[part 1 of 4: packages /MICROSAR/Dcm_swc to /MICROSAR/Dcm_swc/ComponentTypes]
AUTOSAR XML (schema 4-2-2)
package /MICROSAR/Dcm_swc
  mode declaration group DcmEcuReset: category=EXPLICIT_ORDER, initial-mode=NONE, on-transition-value=7
    7 x mode:
      NONE: value=0
      HARD: value=1
      KEYONOFF: value=2
      SOFT: value=3
      JUMPTOBOOTLOADER: value=4
      JUMPTOSYSSUPPLIERBOOTLOADER: value=5
      EXECUTE: value=6
  mode declaration group DcmDiagnosticSessionControl: category=EXPLICIT_ORDER, initial-mode=DEFAULT_SESSION, on-transition-value=255
    mode DEFAULT_SESSION: value=1
    mode PROGRAMMING_SESSION: value=2
    mode EXTENDED_SESSION: value=3
  data type mapping set DcmMappingSet  # Contains mapping for ModeDeclarationGroups which are provided by Dcm.
    mode-request-type-maps:
      implementation-data-type=Dcm_EcuResetType, mode-group=DcmEcuReset
      implementation-data-type=Dcm_DiagnosticSessionControlType, mode-group=DcmDiagnosticSessionControl
package /MICROSAR/Dcm_swc/ComponentTypes
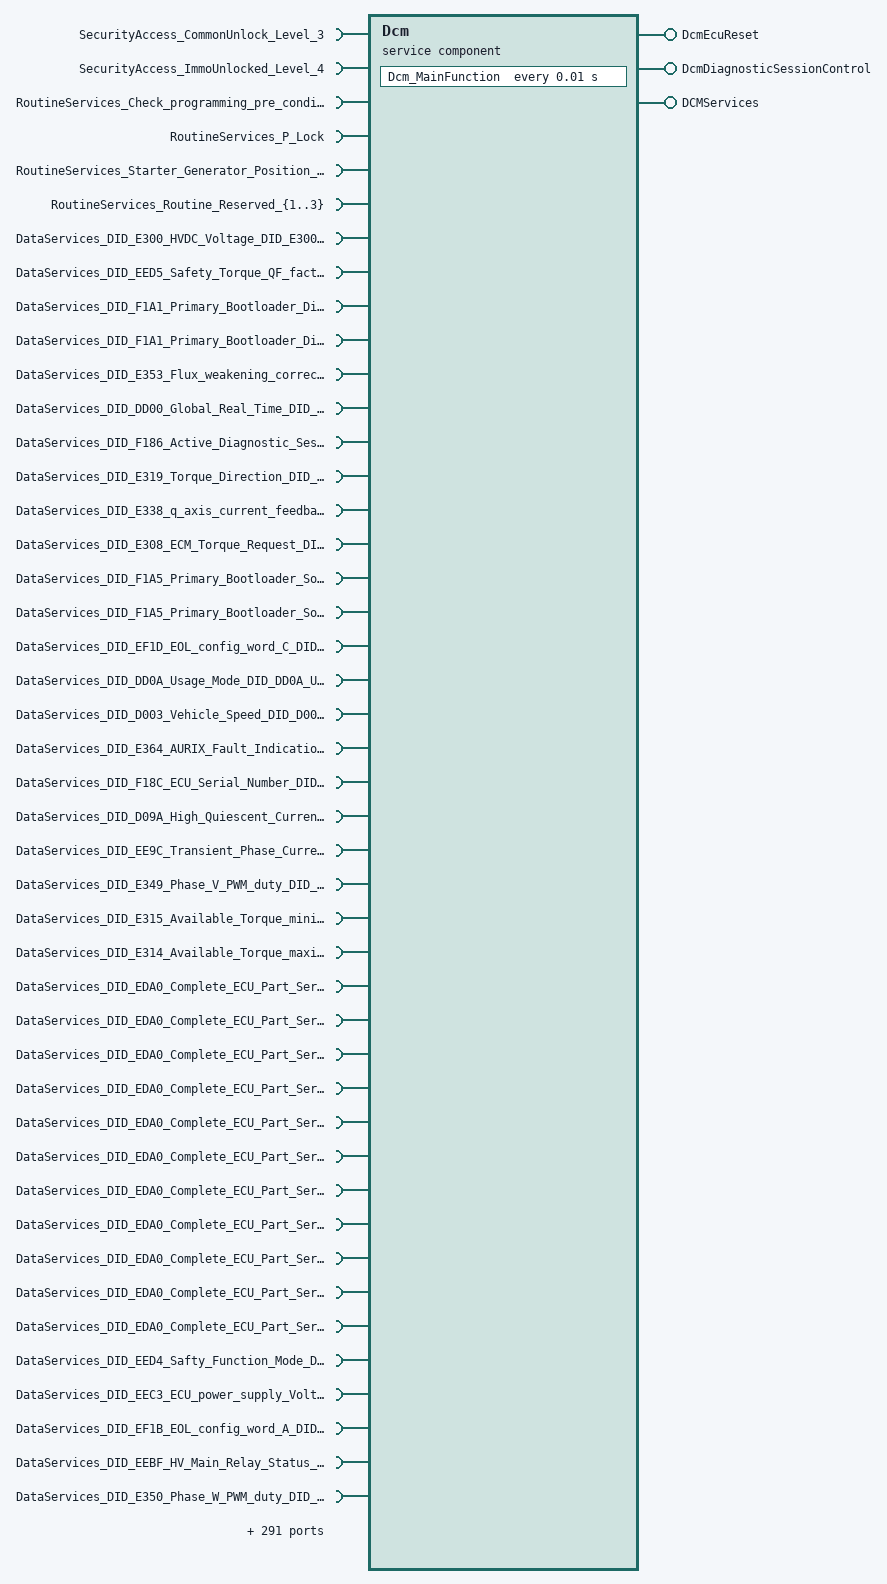
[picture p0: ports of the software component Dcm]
  service sw component type Dcm: category=SERVICE_COMPONENT
    provide port DcmEcuReset: mode-switch-sender-com-spec{mode-group=DcmEcuReset, mode-switched-ack=timeout=0}, provided-interface=DcmEcuReset
    provide port DcmDiagnosticSessionControl: provided-interface=DcmDiagnosticSessionControl
    provide port DCMServices: provided-interface=DCMServices
    346 x require port:
      SecurityAccess_CommonUnlock_Level_3: required-interface=SecurityAccess_CommonUnlock_Level_3
      SecurityAccess_ImmoUnlocked_Level_4: required-interface=SecurityAccess_ImmoUnlocked_Level_4
      RoutineServices_Check_programming_pre_conditions: required-interface=RoutineServices_Check_programming_pre_conditions
      RoutineServices_P_Lock: required-interface=RoutineServices_P_Lock
      RoutineServices_Starter_Generator_Position_Sensors_Calibration: required-interface=RoutineServices_Starter_Generator_Position_Sensors_Calibration
      RoutineServices_Routine_Reserved_{1..3}: required-interface=RoutineServices_Routine_Reserved_{1..3}
      DataServices_DID_E300_HVDC_Voltage_DID_E300_HVDC_Voltage: required-interface=DataServices_DID_E300_HVDC_Voltage_DID_E300_HVDC_Voltage
      DataServices_DID_EED5_Safety_Torque_QF_factor_EED5_Safety_Torque_Quality_factor: required-interface=DataServices_DID_EED5_Safety_Torque_QF_factor_EED5_Safety_Torque_Quality_factor
      DataServices_DID_F1A1_Primary_Bootloader_Diagnostic_Database_Part_Number_Geely_ASCII_part: required-interface=DataServices_DID_F1A1_Primary_Bootloader_Diagnostic_Database_Part_Number_Geely_ASCII_part
      DataServices_DID_F1A1_Primary_Bootloader_Diagnostic_Database_Part_Number_Geely_BCD_part: required-interface=DataServices_DID_F1A1_Primary_Bootloader_Diagnostic_Database_Part_Number_Geely_BCD_part
      DataServices_DID_E353_Flux_weakening_correction_factor_DID_E353_Flux_weakening_correction_factor: required-interface=DataServices_DID_E353_Flux_weakening_correction_factor_DID_E353_Flux_weakening_correction_factor
      DataServices_DID_DD00_Global_Real_Time_DID_DD00_Global_Real_Time: required-interface=DataServices_DID_DD00_Global_Real_Time_DID_DD00_Global_Real_Time
      DataServices_DID_F186_Active_Diagnostic_Session_DID_F186_Active_Diagnostic_Session: required-interface=DataServices_DID_F186_Active_Diagnostic_Session_DID_F186_Active_Diagnostic_Session
      DataServices_DID_E319_Torque_Direction_DID_E319_Torque_Direction: required-interface=DataServices_DID_E319_Torque_Direction_DID_E319_Torque_Direction
      DataServices_DID_E338_q_axis_current_feedback_DID_E338_q_axis_current_feedback: required-interface=DataServices_DID_E338_q_axis_current_feedback_DID_E338_q_axis_current_feedback
      DataServices_DID_E308_ECM_Torque_Request_DID_E308_ECM_Torque_Request: required-interface=DataServices_DID_E308_ECM_Torque_Request_DID_E308_ECM_Torque_Request
      DataServices_DID_F1A5_Primary_Bootloader_Software_Part_Number_Geely_ASCII_part: required-interface=DataServices_DID_F1A5_Primary_Bootloader_Software_Part_Number_Geely_ASCII_part
      DataServices_DID_F1A5_Primary_Bootloader_Software_Part_Number_Geely_BCD_part: required-interface=DataServices_DID_F1A5_Primary_Bootloader_Software_Part_Number_Geely_BCD_part
      DataServices_DID_EF1D_EOL_config_word_C_DID_EF1D_EOL_config_word_C: required-interface=DataServices_DID_EF1D_EOL_config_word_C_DID_EF1D_EOL_config_word_C
      DataServices_DID_DD0A_Usage_Mode_DID_DD0A_Usage_Mode: required-interface=DataServices_DID_DD0A_Usage_Mode_DID_DD0A_Usage_Mode
      DataServices_DID_D003_Vehicle_Speed_DID_D003_Vehicle_Speed: required-interface=DataServices_DID_D003_Vehicle_Speed_DID_D003_Vehicle_Speed
      DataServices_DID_E364_AURIX_Fault_Indication_DID_E364_AURIX_Fault_Indication: required-interface=DataServices_DID_E364_AURIX_Fault_Indication_DID_E364_AURIX_Fault_Indication
      DataServices_DID_F18C_ECU_Serial_Number_DID_F18C_ECU_Serial_Number: required-interface=DataServices_DID_F18C_ECU_Serial_Number_DID_F18C_ECU_Serial_Number
      DataServices_DID_D09A_High_Quiescent_Current_Function_Activation_Deactivation_DID_D09A_High_Quiescent_Current_Function_CD3E51C5: required-interface=DataServices_DID_D09A_High_Quiescent_Current_Function_Activation_Deactivation_DID_D09A_High_Quiescent_Current_Function_CD3E51C5
      DataServices_DID_EE9C_Transient_Phase_Current_A_DID_EE9C_Transient_Phase_Current_A: required-interface=DataServices_DID_EE9C_Transient_Phase_Current_A_DID_EE9C_Transient_Phase_Current_A
      DataServices_DID_E349_Phase_V_PWM_duty_DID_E349_Phase_V_PWM_duty: required-interface=DataServices_DID_E349_Phase_V_PWM_duty_DID_E349_Phase_V_PWM_duty
      DataServices_DID_E315_Available_Torque_minimum_DID_E315_Available_Torque_minimum: required-interface=DataServices_DID_E315_Available_Torque_minimum_DID_E315_Available_Torque_minimum
      DataServices_DID_E314_Available_Torque_maximum_DID_E314_Available_Torque_maximum: required-interface=DataServices_DID_E314_Available_Torque_maximum_DID_E314_Available_Torque_maximum
      DataServices_DID_EDA0_Complete_ECU_Part_Serial_Number_s_DID_F12E_1_Total_number_of_ECU_Software_Part_Numbers: required-interface=DataServices_DID_EDA0_Complete_ECU_Part_Serial_Number_s_DID_F12E_1_Total_number_of_ECU_Software_Part_Numbers
      DataServices_DID_EDA0_Complete_ECU_Part_Serial_Number_s_DID_F12A_ECU_Delivery_Assembly_Part_Number1_1: required-interface=DataServices_DID_EDA0_Complete_ECU_Part_Serial_Number_s_DID_F12A_ECU_Delivery_Assembly_Part_Number1_1
      DataServices_DID_EDA0_Complete_ECU_Part_Serial_Number_s_Reserved: required-interface=DataServices_DID_EDA0_Complete_ECU_Part_Serial_Number_s_Reserved
      DataServices_DID_EDA0_Complete_ECU_Part_Serial_Number_s_DID_F12B_ECU_Delivery_Assembly_Part_Number: required-interface=DataServices_DID_EDA0_Complete_ECU_Part_Serial_Number_s_DID_F12B_ECU_Delivery_Assembly_Part_Number
      DataServices_DID_EDA0_Complete_ECU_Part_Serial_Number_s_DID_F18C_ECU_Serial_Number: required-interface=DataServices_DID_EDA0_Complete_ECU_Part_Serial_Number_s_DID_F18C_ECU_Serial_Number
      DataServices_DID_EDA0_Complete_ECU_Part_Serial_Number_s_ASCII_part: required-interface=DataServices_DID_EDA0_Complete_ECU_Part_Serial_Number_s_ASCII_part
      DataServices_DID_EDA0_Complete_ECU_Part_Serial_Number_s_DID_F12B_ECU_Delivery_Assembly_Part_Number1: required-interface=DataServices_DID_EDA0_Complete_ECU_Part_Serial_Number_s_DID_F12B_ECU_Delivery_Assembly_Part_Number1
      DataServices_DID_EDA0_Complete_ECU_Part_Serial_Number_s_F120_Application_Diagnostic_Database_Part_Number1: required-interface=DataServices_DID_EDA0_Complete_ECU_Part_Serial_Number_s_F120_Application_Diagnostic_Database_Part_Number1
      DataServices_DID_EDA0_Complete_ECU_Part_Serial_Number_s_F120_Application_Diagnostic_Database_Part_Number: required-interface=DataServices_DID_EDA0_Complete_ECU_Part_Serial_Number_s_F120_Application_Diagnostic_Database_Part_Number
      DataServices_DID_EDA0_Complete_ECU_Part_Serial_Number_s_BCD_part: required-interface=DataServices_DID_EDA0_Complete_ECU_Part_Serial_Number_s_BCD_part
      DataServices_DID_EDA0_Complete_ECU_Part_Serial_Number_s_DID_F12A_ECU_Delivery_Assembly_Part_Number_1: required-interface=DataServices_DID_EDA0_Complete_ECU_Part_Serial_Number_s_DID_F12A_ECU_Delivery_Assembly_Part_Number_1
      DataServices_DID_EED4_Safty_Function_Mode_DID_EED4_Safty_Function_Mode: required-interface=DataServices_DID_EED4_Safty_Function_Mode_DID_EED4_Safty_Function_Mode
      DataServices_DID_EEC3_ECU_power_supply_Voltage_DID_EEC3_ECU_power_supply_Voltage: required-interface=DataServices_DID_EEC3_ECU_power_supply_Voltage_DID_EEC3_ECU_power_supply_Voltage
      DataServices_DID_EF1B_EOL_config_word_A_DID_EF1B_EOL_config_word_A: required-interface=DataServices_DID_EF1B_EOL_config_word_A_DID_EF1B_EOL_config_word_A
      DataServices_DID_EEBF_HV_Main_Relay_Status_DID_EEBF_HV_Main_Relay_Status: required-interface=DataServices_DID_EEBF_HV_Main_Relay_Status_DID_EEBF_HV_Main_Relay_Status
      DataServices_DID_E350_Phase_W_PWM_duty_DID_E350_Phase_W_PWM_duty: required-interface=DataServices_DID_E350_Phase_W_PWM_duty_DID_E350_Phase_W_PWM_duty
      DataServices_DID_F126_Autosar_BSW_Cluster_Versions_DID_F126_24_COM_CLUSTER_AR_RELEASE_REVISION_VERSION: required-interface=DataServices_DID_F126_Autosar_BSW_Cluster_Versions_DID_F126_24_COM_CLUSTER_AR_RELEASE_REVISION_VERSION
      DataServices_DID_F126_Autosar_BSW_Cluster_Versions_DID_F126_36_FLEXRAY_CLUSTER_AR_RELEASE_MAJOR_VERSION: required-interface=DataServices_DID_F126_Autosar_BSW_Cluster_Versions_DID_F126_36_FLEXRAY_CLUSTER_AR_RELEASE_MAJOR_VERSION
      DataServices_DID_F126_Autosar_BSW_Cluster_Versions_DID_F126_31_CAN_CLUSTER_AR_RELEASE_REVISION_VERSION: required-interface=DataServices_DID_F126_Autosar_BSW_Cluster_Versions_DID_F126_31_CAN_CLUSTER_AR_RELEASE_REVISION_VERSION
      DataServices_DID_F126_Autosar_BSW_Cluster_Versions_DID_F126_26_CAN_CLUSTER_SW_MAJOR_VERSION: required-interface=DataServices_DID_F126_Autosar_BSW_Cluster_Versions_DID_F126_26_CAN_CLUSTER_SW_MAJOR_VERSION
      DataServices_DID_F126_Autosar_BSW_Cluster_Versions_DID_F126_9_DIAG_CLUSTER_VCC_DCM_VERSION: required-interface=DataServices_DID_F126_Autosar_BSW_Cluster_Versions_DID_F126_9_DIAG_CLUSTER_VCC_DCM_VERSION
      DataServices_DID_F126_Autosar_BSW_Cluster_Versions_DID_F126_40_LIN_CLUSTER_SW_MAJOR_VERSION: required-interface=DataServices_DID_F126_Autosar_BSW_Cluster_Versions_DID_F126_40_LIN_CLUSTER_SW_MAJOR_VERSION
      DataServices_DID_F126_Autosar_BSW_Cluster_Versions_DID_F126_15_MODEMGMT_CLUSTER_AR_RELEASE_MAJOR_VERSION: required-interface=DataServices_DID_F126_Autosar_BSW_Cluster_Versions_DID_F126_15_MODEMGMT_CLUSTER_AR_RELEASE_MAJOR_VERSION
      DataServices_DID_F126_Autosar_BSW_Cluster_Versions_DID_F126_6_DIAG_CLUSTER_AR_RELEASE_MINOR_VERSION: required-interface=DataServices_DID_F126_Autosar_BSW_Cluster_Versions_DID_F126_6_DIAG_CLUSTER_AR_RELEASE_MINOR_VERSION
      DataServices_DID_F126_Autosar_BSW_Cluster_Versions_DID_F126_3_DIAG_CLUSTER_SW_MINOR_VERSION: required-interface=DataServices_DID_F126_Autosar_BSW_Cluster_Versions_DID_F126_3_DIAG_CLUSTER_SW_MINOR_VERSION
      DataServices_DID_F126_Autosar_BSW_Cluster_Versions_DID_F126_8_DIAG_CLUSTER_VCC_DEM_VERSION: required-interface=DataServices_DID_F126_Autosar_BSW_Cluster_Versions_DID_F126_8_DIAG_CLUSTER_VCC_DEM_VERSION
      DataServices_DID_F126_Autosar_BSW_Cluster_Versions_DID_F126_39_LIN_CLUSTER_VENDOR_ID: required-interface=DataServices_DID_F126_Autosar_BSW_Cluster_Versions_DID_F126_39_LIN_CLUSTER_VENDOR_ID
      DataServices_DID_F126_Autosar_BSW_Cluster_Versions_DID_F126_43_LIN_CLUSTER_AR_RELEASE_MAJOR_VERSION: required-interface=DataServices_DID_F126_Autosar_BSW_Cluster_Versions_DID_F126_43_LIN_CLUSTER_AR_RELEASE_MAJOR_VERSION
      DataServices_DID_F126_Autosar_BSW_Cluster_Versions_DID_F126_13_MODEMGMT_CLUSTER_SW_MINOR_VERSION: required-interface=DataServices_DID_F126_Autosar_BSW_Cluster_Versions_DID_F126_13_MODEMGMT_CLUSTER_SW_MINOR_VERSION
      DataServices_DID_F126_Autosar_BSW_Cluster_Versions_DID_F126_23_COM_CLUSTER_AR_RELEASE_MINOR_VERSION: required-interface=DataServices_DID_F126_Autosar_BSW_Cluster_Versions_DID_F126_23_COM_CLUSTER_AR_RELEASE_MINOR_VERSION
      DataServices_DID_F126_Autosar_BSW_Cluster_Versions_DID_F126_20_COM_CLUSTER_SW_MINOR_VERSION: required-interface=DataServices_DID_F126_Autosar_BSW_Cluster_Versions_DID_F126_20_COM_CLUSTER_SW_MINOR_VERSION
      DataServices_DID_F126_Autosar_BSW_Cluster_Versions_DID_F126_16_MODEMGMT_CLUSTER_AR_RELEASE_MINOR_VERSION: required-interface=DataServices_DID_F126_Autosar_BSW_Cluster_Versions_DID_F126_16_MODEMGMT_CLUSTER_AR_RELEASE_MINOR_VERSION
      DataServices_DID_F126_Autosar_BSW_Cluster_Versions_DID_F126_2_DIAG_CLUSTER_SW_MAJOR_VERSION: required-interface=DataServices_DID_F126_Autosar_BSW_Cluster_Versions_DID_F126_2_DIAG_CLUSTER_SW_MAJOR_VERSION
      DataServices_DID_F126_Autosar_BSW_Cluster_Versions_DID_F126_35_FLEXRAY_CLUSTER_SW_PATCH_VERSION: required-interface=DataServices_DID_F126_Autosar_BSW_Cluster_Versions_DID_F126_35_FLEXRAY_CLUSTER_SW_PATCH_VERSION
      DataServices_DID_F126_Autosar_BSW_Cluster_Versions_DID_F126_17_MODEMGMT_CLUSTER_AR_RELEASE_REVISION_VERSION: required-interface=DataServices_DID_F126_Autosar_BSW_Cluster_Versions_DID_F126_17_MODEMGMT_CLUSTER_AR_RELEASE_REVISION_VERSION
      DataServices_DID_F126_Autosar_BSW_Cluster_Versions_DID_F126_4_DIAG_CLUSTER_SW_PATCH_VERSION: required-interface=DataServices_DID_F126_Autosar_BSW_Cluster_Versions_DID_F126_4_DIAG_CLUSTER_SW_PATCH_VERSION
      DataServices_DID_F126_Autosar_BSW_Cluster_Versions_DID_F126_27_CAN_CLUSTER_SW_MINOR_VERSION: required-interface=DataServices_DID_F126_Autosar_BSW_Cluster_Versions_DID_F126_27_CAN_CLUSTER_SW_MINOR_VERSION
      DataServices_DID_F126_Autosar_BSW_Cluster_Versions_DID_F126_7_DIAG_CLUSTER_AR_RELEASE_REVISION_VERSION: required-interface=DataServices_DID_F126_Autosar_BSW_Cluster_Versions_DID_F126_7_DIAG_CLUSTER_AR_RELEASE_REVISION_VERSION
      DataServices_DID_F126_Autosar_BSW_Cluster_Versions_DID_F126_11_MODEMGMT_CLUSTER_VENDOR_ID: required-interface=DataServices_DID_F126_Autosar_BSW_Cluster_Versions_DID_F126_11_MODEMGMT_CLUSTER_VENDOR_ID
      DataServices_DID_F126_Autosar_BSW_Cluster_Versions_DID_F126_34_FLEXRAY_CLUSTER_SW_MINOR_VERSION: required-interface=DataServices_DID_F126_Autosar_BSW_Cluster_Versions_DID_F126_34_FLEXRAY_CLUSTER_SW_MINOR_VERSION
      DataServices_DID_F126_Autosar_BSW_Cluster_Versions_DID_F126_5_DIAG_CLUSTER_AR_RELEASE_MAJOR_VERSION: required-interface=DataServices_DID_F126_Autosar_BSW_Cluster_Versions_DID_F126_5_DIAG_CLUSTER_AR_RELEASE_MAJOR_VERSION
      DataServices_DID_F126_Autosar_BSW_Cluster_Versions_DID_F126_28_CAN_CLUSTER_SW_PATCH_VERSION: required-interface=DataServices_DID_F126_Autosar_BSW_Cluster_Versions_DID_F126_28_CAN_CLUSTER_SW_PATCH_VERSION
      DataServices_DID_F126_Autosar_BSW_Cluster_Versions_DID_F126_25_CAN_CLUSTER_VENDOR_ID: required-interface=DataServices_DID_F126_Autosar_BSW_Cluster_Versions_DID_F126_25_CAN_CLUSTER_VENDOR_ID
      DataServices_DID_F126_Autosar_BSW_Cluster_Versions_DID_F126_42_LIN_CLUSTER_SW_PATCH_VERSION: required-interface=DataServices_DID_F126_Autosar_BSW_Cluster_Versions_DID_F126_42_LIN_CLUSTER_SW_PATCH_VERSION
      DataServices_DID_F126_Autosar_BSW_Cluster_Versions_DID_F126_19_COM_CLUSTER_SW_MAJOR_VERSION: required-interface=DataServices_DID_F126_Autosar_BSW_Cluster_Versions_DID_F126_19_COM_CLUSTER_SW_MAJOR_VERSION
      DataServices_DID_F126_Autosar_BSW_Cluster_Versions_DID_F126_30_CAN_CLUSTER_AR_RELEASE_MINOR_VERSION: required-interface=DataServices_DID_F126_Autosar_BSW_Cluster_Versions_DID_F126_30_CAN_CLUSTER_AR_RELEASE_MINOR_VERSION
      DataServices_DID_F126_Autosar_BSW_Cluster_Versions_DID_F126_21_COM_CLUSTER_SW_PATCH_VERSION: required-interface=DataServices_DID_F126_Autosar_BSW_Cluster_Versions_DID_F126_21_COM_CLUSTER_SW_PATCH_VERSION
      DataServices_DID_F126_Autosar_BSW_Cluster_Versions_DID_F126_14_MODEMGMT_CLUSTER_SW_PATCH_VERSION: required-interface=DataServices_DID_F126_Autosar_BSW_Cluster_Versions_DID_F126_14_MODEMGMT_CLUSTER_SW_PATCH_VERSION
      DataServices_DID_F126_Autosar_BSW_Cluster_Versions_DID_F126_1_DIAG_CLUSTER_VENDOR_ID: required-interface=DataServices_DID_F126_Autosar_BSW_Cluster_Versions_DID_F126_1_DIAG_CLUSTER_VENDOR_ID
      DataServices_DID_F126_Autosar_BSW_Cluster_Versions_DID_F126_41_LIN_CLUSTER_SW_MINOR_VERSION: required-interface=DataServices_DID_F126_Autosar_BSW_Cluster_Versions_DID_F126_41_LIN_CLUSTER_SW_MINOR_VERSION
      DataServices_DID_F126_Autosar_BSW_Cluster_Versions_DID_F126_10_DIAG_CLUSTER_VCC_FIM_VERSION: required-interface=DataServices_DID_F126_Autosar_BSW_Cluster_Versions_DID_F126_10_DIAG_CLUSTER_VCC_FIM_VERSION
      DataServices_DID_F126_Autosar_BSW_Cluster_Versions_DID_F126_18_COM_CLUSTER_VENDOR_ID: required-interface=DataServices_DID_F126_Autosar_BSW_Cluster_Versions_DID_F126_18_COM_CLUSTER_VENDOR_ID
      DataServices_DID_F126_Autosar_BSW_Cluster_Versions_DID_F126_38_FLEXRAY_CLUSTER_AR_RELEASE_REVISION_VERSION: required-interface=DataServices_DID_F126_Autosar_BSW_Cluster_Versions_DID_F126_38_FLEXRAY_CLUSTER_AR_RELEASE_REVISION_VERSION
      DataServices_DID_F126_Autosar_BSW_Cluster_Versions_DID_F126_32_FLEXRAY_CLUSTER_VENDOR_ID: required-interface=DataServices_DID_F126_Autosar_BSW_Cluster_Versions_DID_F126_32_FLEXRAY_CLUSTER_VENDOR_ID
      DataServices_DID_F126_Autosar_BSW_Cluster_Versions_DID_F126_12_MODEMGMT_CLUSTER_SW_MAJOR_VERSION: required-interface=DataServices_DID_F126_Autosar_BSW_Cluster_Versions_DID_F126_12_MODEMGMT_CLUSTER_SW_MAJOR_VERSION
      DataServices_DID_F126_Autosar_BSW_Cluster_Versions_DID_F126_29_CAN_CLUSTER_AR_RELEASE_MAJOR_VERSION: required-interface=DataServices_DID_F126_Autosar_BSW_Cluster_Versions_DID_F126_29_CAN_CLUSTER_AR_RELEASE_MAJOR_VERSION
      DataServices_DID_F126_Autosar_BSW_Cluster_Versions_DID_F126_22_COM_CLUSTER_AR_RELEASE_MAJOR_VERSION: required-interface=DataServices_DID_F126_Autosar_BSW_Cluster_Versions_DID_F126_22_COM_CLUSTER_AR_RELEASE_MAJOR_VERSION
      DataServices_DID_F126_Autosar_BSW_Cluster_Versions_DID_F126_44_LIN_CLUSTER_AR_RELEASE_MINOR_VERSION: required-interface=DataServices_DID_F126_Autosar_BSW_Cluster_Versions_DID_F126_44_LIN_CLUSTER_AR_RELEASE_MINOR_VERSION
      DataServices_DID_F126_Autosar_BSW_Cluster_Versions_DID_F126_37_FLEXRAY_CLUSTER_AR_RELEASE_MINOR_VERSION: required-interface=DataServices_DID_F126_Autosar_BSW_Cluster_Versions_DID_F126_37_FLEXRAY_CLUSTER_AR_RELEASE_MINOR_VERSION
      DataServices_DID_F126_Autosar_BSW_Cluster_Versions_DID_F126_45_LIN_CLUSTER_AR_RELEASE_REVISION_VERSION: required-interface=DataServices_DID_F126_Autosar_BSW_Cluster_Versions_DID_F126_45_LIN_CLUSTER_AR_RELEASE_REVISION_VERSION
      DataServices_DID_F126_Autosar_BSW_Cluster_Versions_DID_F126_33_FLEXRAY_CLUSTER_SW_MAJOR_VERSION: required-interface=DataServices_DID_F126_Autosar_BSW_Cluster_Versions_DID_F126_33_FLEXRAY_CLUSTER_SW_MAJOR_VERSION
      DataServices_DID_E337_q_axis_current_setpoint_DID_E337_q_axis_current_setpoint: required-interface=DataServices_DID_E337_q_axis_current_setpoint_DID_E337_q_axis_current_setpoint
      DataServices_DID_ED20_Complete_set_of_ECU_part_serial_numbers_Geely_BCD_part_003: required-interface=DataServices_DID_ED20_Complete_set_of_ECU_part_serial_numbers_Geely_BCD_part_003
      DataServices_DID_ED20_Complete_set_of_ECU_part_serial_numbers_Geely_BCD_part_001: required-interface=DataServices_DID_ED20_Complete_set_of_ECU_part_serial_numbers_Geely_BCD_part_001
      DataServices_DID_ED20_Complete_set_of_ECU_part_serial_numbers_Geely_BCD_part_002: required-interface=DataServices_DID_ED20_Complete_set_of_ECU_part_serial_numbers_Geely_BCD_part_002
      DataServices_DID_ED20_Complete_set_of_ECU_part_serial_numbers_Geely_Reserved: required-interface=DataServices_DID_ED20_Complete_set_of_ECU_part_serial_numbers_Geely_Reserved
      DataServices_DID_ED20_Complete_set_of_ECU_part_serial_numbers_Geely_DID_F1AE_1_Total_number_of_ECU_Software_Part_Numbers: required-interface=DataServices_DID_ED20_Complete_set_of_ECU_part_serial_numbers_Geely_DID_F1AE_1_Total_number_of_ECU_Software_Part_Numbers
      DataServices_DID_ED20_Complete_set_of_ECU_part_serial_numbers_Geely_DID_F18C_ECU_Serial_Number: required-interface=DataServices_DID_ED20_Complete_set_of_ECU_part_serial_numbers_Geely_DID_F18C_ECU_Serial_Number
      DataServices_DID_ED20_Complete_set_of_ECU_part_serial_numbers_Geely_ASCII_part_{001..003}: required-interface=DataServices_DID_ED20_Complete_set_of_ECU_part_serial_numbers_Geely_ASCII_part_{001..003}
      DataServices_DID_ED20_Complete_set_of_ECU_part_serial_numbers_Geely_ASCII_part: required-interface=DataServices_DID_ED20_Complete_set_of_ECU_part_serial_numbers_Geely_ASCII_part
      DataServices_DID_ED20_Complete_set_of_ECU_part_serial_numbers_Geely_BCD_part: required-interface=DataServices_DID_ED20_Complete_set_of_ECU_part_serial_numbers_Geely_BCD_part
      DataServices_DID_E339_d_axis_voltage_DID_E339_d_axis_voltage: required-interface=DataServices_DID_E339_d_axis_voltage_DID_E339_d_axis_voltage
      DataServices_DID_EEB5_IEM_MGM_current_torque_DID_EEB5_IEMMGM_current_torque: required-interface=DataServices_DID_EEB5_IEM_MGM_current_torque_DID_EEB5_IEMMGM_current_torque
      DataServices_DID_F121_Primary_Bootloader_Diagnostic_Database_Part_Number_ASCII_part: required-interface=DataServices_DID_F121_Primary_Bootloader_Diagnostic_Database_Part_Number_ASCII_part
      DataServices_DID_F121_Primary_Bootloader_Diagnostic_Database_Part_Number_BCD_part: required-interface=DataServices_DID_F121_Primary_Bootloader_Diagnostic_Database_Part_Number_BCD_part
      DataServices_DID_D0B5_SDB_version_SDB_version: required-interface=DataServices_DID_D0B5_SDB_version_SDB_version
      DataServices_DID_D12F_Security_Constant_Level_11_12_DID_D12F_Security_Constant_Level_1112: required-interface=DataServices_DID_D12F_Security_Constant_Level_11_12_DID_D12F_Security_Constant_Level_1112
      DataServices_DID_E313_Active_discharge_status_DID_E313_Active_discharge_status: required-interface=DataServices_DID_E313_Active_discharge_status_DID_E313_Active_discharge_status
      DataServices_DID_DD02_Vehicle_Battery_Voltage_DID_DD02_Vehicle_Battery_Voltage: required-interface=DataServices_DID_DD02_Vehicle_Battery_Voltage_DID_DD02_Vehicle_Battery_Voltage
      DataServices_DID_E312_Wheel_Speed_DID_E312_Wheel_Speed: required-interface=DataServices_DID_E312_Wheel_Speed_DID_E312_Wheel_Speed
      DataServices_DID_E363_Modulation_index_DID_E363_Modulation_index: required-interface=DataServices_DID_E363_Modulation_index_DID_E363_Modulation_index
      DataServices_DID_D03A_swAuth_Public_Key_CheckSum_DID_D03A_swAuth_Public_Key_CheckSum: required-interface=DataServices_DID_D03A_swAuth_Public_Key_CheckSum_DID_D03A_swAuth_Public_Key_CheckSum
      DataServices_DID_E347_IGBT_Max_Temperature_DID_E347_IGBT_Max_Temperature: required-interface=DataServices_DID_E347_IGBT_Max_Temperature_DID_E347_IGBT_Max_Temperature
      DataServices_DID_F1AB_ECU_Delivery_Assembly_Part_Number_Geely_ASCII_part: required-interface=DataServices_DID_F1AB_ECU_Delivery_Assembly_Part_Number_Geely_ASCII_part
      DataServices_DID_F1AB_ECU_Delivery_Assembly_Part_Number_Geely_BCD_part: required-interface=DataServices_DID_F1AB_ECU_Delivery_Assembly_Part_Number_Geely_BCD_part
      DataServices_DID_E336_d_axis_current_feedback_DID_E336_d_axis_current_feedback: required-interface=DataServices_DID_E336_d_axis_current_feedback_DID_E336_d_axis_current_feedback
      DataServices_DID_EE9D_Transient_Phase_Current_B_DID_EE9D_Transient_Phase_Current_B: required-interface=DataServices_DID_EE9D_Transient_Phase_Current_B_DID_EE9D_Transient_Phase_Current_B
      DataServices_DID_EE9F_Gate_Status_DID_EE9F_Gate_Status: required-interface=DataServices_DID_EE9F_Gate_Status_DID_EE9F_Gate_Status
      DataServices_DID_E333_2002_State_2002_H_Ser: required-interface=DataServices_DID_E333_2002_State_2002_H_Ser
      DataServices_DID_E333_2002_State_2002_Lu: required-interface=DataServices_DID_E333_2002_State_2002_Lu
      DataServices_DID_E333_2002_State_2002_L_Ser: required-interface=DataServices_DID_E333_2002_State_2002_L_Ser
      DataServices_DID_E333_2002_State_2002_Hu: required-interface=DataServices_DID_E333_2002_State_2002_Hu
      DataServices_DID_E333_2002_State_2002_Lv: required-interface=DataServices_DID_E333_2002_State_2002_Lv
      DataServices_DID_E333_2002_State_2002_Lw: required-interface=DataServices_DID_E333_2002_State_2002_Lw
      DataServices_DID_E333_2002_State_2002_Hv: required-interface=DataServices_DID_E333_2002_State_2002_Hv
      DataServices_DID_E333_2002_State_2002_Hw: required-interface=DataServices_DID_E333_2002_State_2002_Hw
      DataServices_DID_E310_IEM_MGM_Derating_Status_DID_E310_IEMMGM_Derating_Status: required-interface=DataServices_DID_E310_IEM_MGM_Derating_Status_DID_E310_IEMMGM_Derating_Status
      DataServices_DID_EEBE_Offset_angle_status_DID_EEBE_Offset_angle_status: required-interface=DataServices_DID_EEBE_Offset_angle_status_DID_EEBE_Offset_angle_status
      DataServices_Application_Diagnostic_Database_Part_Number_Partnumber_Variant: required-interface=DataServices_Application_Diagnostic_Database_Part_Number_Partnumber_Variant
      DataServices_Application_Diagnostic_Database_Part_Number_Partnumber_Main: required-interface=DataServices_Application_Diagnostic_Database_Part_Number_Partnumber_Main
      DataServices_DID_0xEEC7_1_DID_EED2_SaftyTorque: required-interface=DataServices_DID_0xEEC7_1_DID_EED2_SaftyTorque
      DataServices_DID_E358_Resolve_angle_DID_E358_Resolve_angle: required-interface=DataServices_DID_E358_Resolve_angle_DID_E358_Resolve_angle
      DataServices_DID_E357_Resolve_compensated_angle_DID_E357_Resolve_compensated_angle: required-interface=DataServices_DID_E357_Resolve_compensated_angle_DID_E357_Resolve_compensated_angle
      DataServices_DID_E307_System_Mode_DID_E307_System_Mode: required-interface=DataServices_DID_E307_System_Mode_DID_E307_System_Mode
      DataServices_DID_E305_Inverter_IGBT_Junction_Temp_DID_E305_Inverter_IGBT_Junction_Temp: required-interface=DataServices_DID_E305_Inverter_IGBT_Junction_Temp_DID_E305_Inverter_IGBT_Junction_Temp
      DataServices_DID_F1AA_ECU_Core_Assembly_Part_Number_Geely_ASCII_part: required-interface=DataServices_DID_F1AA_ECU_Core_Assembly_Part_Number_Geely_ASCII_part
      DataServices_DID_F1AA_ECU_Core_Assembly_Part_Number_Geely_BCD_part: required-interface=DataServices_DID_F1AA_ECU_Core_Assembly_Part_Number_Geely_BCD_part
      DataServices_DID_E301_HVDC_Current_DID_E301_HVDC_Current_: required-interface=DataServices_DID_E301_HVDC_Current_DID_E301_HVDC_Current_
      DataServices_DID_EF1C_EOL_config_word_B_DID_EF1C_EOL_config_word_B: required-interface=DataServices_DID_EF1C_EOL_config_word_B_DID_EF1C_EOL_config_word_B
      DataServices_DID_EEBD_IEM_MGM_rotor_offset_angle_DID_EEBD_IEMMGM_rotor_offset_angle: required-interface=DataServices_DID_EEBD_IEM_MGM_rotor_offset_angle_DID_EEBD_IEMMGM_rotor_offset_angle
      DataServices_DID_E306_Motor_Temperature_DID_E306_Motor_Temperature: required-interface=DataServices_DID_E306_Motor_Temperature_DID_E306_Motor_Temperature
      DataServices_DID_EED1_Safty_monitor_Fault_Indication_EED1_{1..3}: required-interface=DataServices_DID_EED1_Safty_monitor_Fault_Indication_EED1_{1..3}
      DataServices_DID_EED1_Safty_monitor_Fault_Indication_EED1_0: required-interface=DataServices_DID_EED1_Safty_monitor_Fault_Indication_EED1_0
      DataServices_DID_EEB7_ECM_Power_Limitation_minimum_DID_EEB7_ECM_Power_Limitation_minimum: required-interface=DataServices_DID_EEB7_ECM_Power_Limitation_minimum_DID_EEB7_ECM_Power_Limitation_minimum
      DataServices_DID_F12E_ECU_Software_Part_Numbers_ASCII_part: required-interface=DataServices_DID_F12E_ECU_Software_Part_Numbers_ASCII_part
      DataServices_DID_F12E_ECU_Software_Part_Numbers_DID_F12E_1_ECU_Software: required-interface=DataServices_DID_F12E_ECU_Software_Part_Numbers_DID_F12E_1_ECU_Software
      DataServices_DID_F12E_ECU_Software_Part_Numbers_BCD_part: required-interface=DataServices_DID_F12E_ECU_Software_Part_Numbers_BCD_part
      DataServices_DID_F1AE_ECU_Software_Part_Numbers_Geely_DID_F1AE_1_Total_number_of_ECU_Software_Part_Numbers: required-interface=DataServices_DID_F1AE_ECU_Software_Part_Numbers_Geely_DID_F1AE_1_Total_number_of_ECU_Software_Part_Numbers
      DataServices_DID_F1AE_ECU_Software_Part_Numbers_Geely_ASCII_part: required-interface=DataServices_DID_F1AE_ECU_Software_Part_Numbers_Geely_ASCII_part
      DataServices_DID_F1AE_ECU_Software_Part_Numbers_Geely_BCD_part: required-interface=DataServices_DID_F1AE_ECU_Software_Part_Numbers_Geely_BCD_part
      DataServices_DID_F125_Primary_Bootloader_Software_Part_Number_ASCII_part: required-interface=DataServices_DID_F125_Primary_Bootloader_Software_Part_Number_ASCII_part
      DataServices_DID_F125_Primary_Bootloader_Software_Part_Number_BCD_part: required-interface=DataServices_DID_F125_Primary_Bootloader_Software_Part_Number_BCD_part
      DataServices_DID_EEFD_Sofware_Project_Version_DID_EEFD_Clutch_Control_Fault_Indication: required-interface=DataServices_DID_EEFD_Sofware_Project_Version_DID_EEFD_Clutch_Control_Fault_Indication
      DataServices_DID_E304_Actual_Torque_DID_E304_Actual_Torque: required-interface=DataServices_DID_E304_Actual_Torque_DID_E304_Actual_Torque
      DataServices_DID_D134_Car_Mode_DID_D134_Car_Mode: required-interface=DataServices_DID_D134_Car_Mode_DID_D134_Car_Mode
      DataServices_DID_E335_d_axis_current_setpoint_DID_E335_d_axis_current_setpoint: required-interface=DataServices_DID_E335_d_axis_current_setpoint_DID_E335_d_axis_current_setpoint
      DataServices_DID_EEB2_Three_Phase_Motor_Current_RMS_Current_DID_EEB2_Three_Phase_Motor_Current_RMS_Current: required-interface=DataServices_DID_EEB2_Three_Phase_Motor_Current_RMS_Current_DID_EEB2_Three_Phase_Motor_Current_RMS_Current
      DataServices_DID_E341_q_axis_voltage_DID_E341_q_axis_voltage: required-interface=DataServices_DID_E341_q_axis_voltage_DID_E341_q_axis_voltage
      DataServices_DID_EE9A_Inverter_Coolant_Temperature_DID_EE9A_Inverter_Coolant_Temperature: required-interface=DataServices_DID_EE9A_Inverter_Coolant_Temperature_DID_EE9A_Inverter_Coolant_Temperature
      DataServices_DID_EEB6_ECM_Power_Limitation_maximum_DID_EEB6_ECM_Power_Limitation_maximum: required-interface=DataServices_DID_EEB6_ECM_Power_Limitation_maximum_DID_EEB6_ECM_Power_Limitation_maximum
      DataServices_DID_F1AF_ECU_Software_Extended_Part_Numbers_Geely_DID_F1AF_1_Total_number_of_ECU_Software_Part_Numbers: required-interface=DataServices_DID_F1AF_ECU_Software_Extended_Part_Numbers_Geely_DID_F1AF_1_Total_number_of_ECU_Software_Part_Numbers
      DataServices_DID_F1AF_ECU_Software_Extended_Part_Numbers_Geely_BCD_part_003: required-interface=DataServices_DID_F1AF_ECU_Software_Extended_Part_Numbers_Geely_BCD_part_003
      DataServices_DID_F1AF_ECU_Software_Extended_Part_Numbers_Geely_BCD_part_001: required-interface=DataServices_DID_F1AF_ECU_Software_Extended_Part_Numbers_Geely_BCD_part_001
      DataServices_DID_F1AF_ECU_Software_Extended_Part_Numbers_Geely_BCD_part_002: required-interface=DataServices_DID_F1AF_ECU_Software_Extended_Part_Numbers_Geely_BCD_part_002
      DataServices_DID_F1AF_ECU_Software_Extended_Part_Numbers_Geely_ASCII_part_{001..003}: required-interface=DataServices_DID_F1AF_ECU_Software_Extended_Part_Numbers_Geely_ASCII_part_{001..003}
      DataServices_DID_F1AF_ECU_Software_Extended_Part_Numbers_Geely_ASCII_part: required-interface=DataServices_DID_F1AF_ECU_Software_Extended_Part_Numbers_Geely_ASCII_part
      DataServices_DID_F1AF_ECU_Software_Extended_Part_Numbers_Geely_BCD_part: required-interface=DataServices_DID_F1AF_ECU_Software_Extended_Part_Numbers_Geely_BCD_part
      DataServices_DID_E331_Software_Version_DID_E331_2_BSW_Software_Version: required-interface=DataServices_DID_E331_Software_Version_DID_E331_2_BSW_Software_Version
      DataServices_DID_E331_Software_Version_DID_E331_3_Calibration_Data_Software_Version: required-interface=DataServices_DID_E331_Software_Version_DID_E331_3_Calibration_Data_Software_Version
      DataServices_DID_E331_Software_Version_DID_E331_1_ASW_Software_Version: required-interface=DataServices_DID_E331_Software_Version_DID_E331_1_ASW_Software_Version
      DataServices_DID_EE9E_Transient_Phase_Current_C_DID_EE9E_Transient_Phase_Current_C: required-interface=DataServices_DID_EE9E_Transient_Phase_Current_C_DID_EE9E_Transient_Phase_Current_C
      DataServices_DID_D005_High_Quiescent_Current_Fault_Identification_Data_DID_D005_5st_Usage_Mode_when_DID_is_triggered: required-interface=DataServices_DID_D005_High_Quiescent_Current_Fault_Identification_Data_DID_D005_5st_Usage_Mode_when_DID_is_triggered
      DataServices_DID_D005_High_Quiescent_Current_Fault_Identification_Data_DID_D005_5st_System_Global_Time_the_time_when_th_C1151891: required-interface=DataServices_DID_D005_High_Quiescent_Current_Fault_Identification_Data_DID_D005_5st_System_Global_Time_the_time_when_th_C1151891
      DataServices_DID_D005_High_Quiescent_Current_Fault_Identification_Data_DID_D005_1st_Usage_Mode_when_DID_is_triggered: required-interface=DataServices_DID_D005_High_Quiescent_Current_Fault_Identification_Data_DID_D005_1st_Usage_Mode_when_DID_is_triggered
      DataServices_DID_D005_High_Quiescent_Current_Fault_Identification_Data_D005_4st_Functionality_Activity_Level_PNC39: required-interface=DataServices_DID_D005_High_Quiescent_Current_Fault_Identification_Data_D005_4st_Functionality_Activity_Level_PNC39
      DataServices_DID_D005_High_Quiescent_Current_Fault_Identification_Data_Bitfield_4th: required-interface=DataServices_DID_D005_High_Quiescent_Current_Fault_Identification_Data_Bitfield_4th
      DataServices_DID_D005_High_Quiescent_Current_Fault_Identification_Data_D005_1st_Functionality_Activity_Level_PNC26: required-interface=DataServices_DID_D005_High_Quiescent_Current_Fault_Identification_Data_D005_1st_Functionality_Activity_Level_PNC26
      DataServices_DID_D005_High_Quiescent_Current_Fault_Identification_Data_D005_1st_Functionality_Activity_Level_PNC27: required-interface=DataServices_DID_D005_High_Quiescent_Current_Fault_Identification_Data_D005_1st_Functionality_Activity_Level_PNC27
      DataServices_DID_D005_High_Quiescent_Current_Fault_Identification_Data_Bitfield_2th: required-interface=DataServices_DID_D005_High_Quiescent_Current_Fault_Identification_Data_Bitfield_2th
      DataServices_DID_D005_High_Quiescent_Current_Fault_Identification_Data_Functionality_Activity_Level_Detect_CPSR_Keep_Active_2st: required-interface=DataServices_DID_D005_High_Quiescent_Current_Fault_Identification_Data_Functionality_Activity_Level_Detect_CPSR_Keep_Active_2st
      DataServices_DID_D005_High_Quiescent_Current_Fault_Identification_Data_D005_1st_Functionality_Activity_Level_PNC29: required-interface=DataServices_DID_D005_High_Quiescent_Current_Fault_Identification_Data_D005_1st_Functionality_Activity_Level_PNC29
      DataServices_DID_D005_High_Quiescent_Current_Fault_Identification_Data_D005_1st_Functionality_Activity_Level_PNC24: required-interface=DataServices_DID_D005_High_Quiescent_Current_Fault_Identification_Data_D005_1st_Functionality_Activity_Level_PNC24
      DataServices_DID_D005_High_Quiescent_Current_Fault_Identification_Data_D005_1st_Functionality_Activity_Level_PNC25: required-interface=DataServices_DID_D005_High_Quiescent_Current_Fault_Identification_Data_D005_1st_Functionality_Activity_Level_PNC25
      DataServices_DID_D005_High_Quiescent_Current_Fault_Identification_Data_Reserved_PNC_2st: required-interface=DataServices_DID_D005_High_Quiescent_Current_Fault_Identification_Data_Reserved_PNC_2st
      DataServices_DID_D005_High_Quiescent_Current_Fault_Identification_Data_D005_1st_Functionality_Activity_Level_PNC30: required-interface=DataServices_DID_D005_High_Quiescent_Current_Fault_Identification_Data_D005_1st_Functionality_Activity_Level_PNC30
      DataServices_DID_D005_High_Quiescent_Current_Fault_Identification_Data_Functionality_Activity_Level_Detect_CPSR_Keep_Active_4st: required-interface=DataServices_DID_D005_High_Quiescent_Current_Fault_Identification_Data_Functionality_Activity_Level_Detect_CPSR_Keep_Active_4st
      DataServices_DID_D005_High_Quiescent_Current_Fault_Identification_Data_Reserved_PNC_4st: required-interface=DataServices_DID_D005_High_Quiescent_Current_Fault_Identification_Data_Reserved_PNC_4st
      DataServices_DID_D005_High_Quiescent_Current_Fault_Identification_Data_Functionality_Activity_Level_Detect_Motor_Speed_AE735753: required-interface=DataServices_DID_D005_High_Quiescent_Current_Fault_Identification_Data_Functionality_Activity_Level_Detect_Motor_Speed_AE735753
      DataServices_DID_D005_High_Quiescent_Current_Fault_Identification_Data_D005_2st_Functionality_Activity_Level_PNC39: required-interface=DataServices_DID_D005_High_Quiescent_Current_Fault_Identification_Data_D005_2st_Functionality_Activity_Level_PNC39
      DataServices_DID_D005_High_Quiescent_Current_Fault_Identification_Data_Functionality_Activity_Level_Detect_Motor_Speed_AE736657: required-interface=DataServices_DID_D005_High_Quiescent_Current_Fault_Identification_Data_Functionality_Activity_Level_Detect_Motor_Speed_AE736657
      DataServices_DID_D005_High_Quiescent_Current_Fault_Identification_Data_Functionality_Activity_Level_Detect_Motor_Speed_AE735ED5: required-interface=DataServices_DID_D005_High_Quiescent_Current_Fault_Identification_Data_Functionality_Activity_Level_Detect_Motor_Speed_AE735ED5
      DataServices_DID_D005_High_Quiescent_Current_Fault_Identification_Data_D005_2st_Functionality_Activity_Level_PNC35: required-interface=DataServices_DID_D005_High_Quiescent_Current_Fault_Identification_Data_D005_2st_Functionality_Activity_Level_PNC35
      DataServices_DID_D005_High_Quiescent_Current_Fault_Identification_Data_D005_4st_Functionality_Activity_Level_PNC29: required-interface=DataServices_DID_D005_High_Quiescent_Current_Fault_Identification_Data_D005_4st_Functionality_Activity_Level_PNC29
      DataServices_DID_D005_High_Quiescent_Current_Fault_Identification_Data_DID_D005_5st_Global_time_when_Functionality_Acti_183F5278: required-interface=DataServices_DID_D005_High_Quiescent_Current_Fault_Identification_Data_DID_D005_5st_Global_time_when_Functionality_Acti_183F5278
      DataServices_DID_D005_High_Quiescent_Current_Fault_Identification_Data_DID_D005_2st_Usage_Mode_when_DID_is_triggered: required-interface=DataServices_DID_D005_High_Quiescent_Current_Fault_Identification_Data_DID_D005_2st_Usage_Mode_when_DID_is_triggered
      DataServices_DID_D005_High_Quiescent_Current_Fault_Identification_Data_D005_2st_Functionality_Activity_Level_PNC30: required-interface=DataServices_DID_D005_High_Quiescent_Current_Fault_Identification_Data_D005_2st_Functionality_Activity_Level_PNC30
      DataServices_DID_D005_High_Quiescent_Current_Fault_Identification_Data_D005_4st_Functionality_Activity_Level_PNC25: required-interface=DataServices_DID_D005_High_Quiescent_Current_Fault_Identification_Data_D005_4st_Functionality_Activity_Level_PNC25
      DataServices_DID_D005_High_Quiescent_Current_Fault_Identification_Data_Reserved_Data_Field_4st: required-interface=DataServices_DID_D005_High_Quiescent_Current_Fault_Identification_Data_Reserved_Data_Field_4st
      DataServices_DID_D005_High_Quiescent_Current_Fault_Identification_Data_D005_4st_Functionality_Activity_Level_PNC26: required-interface=DataServices_DID_D005_High_Quiescent_Current_Fault_Identification_Data_D005_4st_Functionality_Activity_Level_PNC26
      DataServices_DID_D005_High_Quiescent_Current_Fault_Identification_Data_D005_4st_Functionality_Activity_Level_PNC27: required-interface=DataServices_DID_D005_High_Quiescent_Current_Fault_Identification_Data_D005_4st_Functionality_Activity_Level_PNC27
      DataServices_DID_D005_High_Quiescent_Current_Fault_Identification_Data_Functionality_Activity_Level_Detect_DC_Bus_volta_2AFD19A5: required-interface=DataServices_DID_D005_High_Quiescent_Current_Fault_Identification_Data_Functionality_Activity_Level_Detect_DC_Bus_volta_2AFD19A5
      DataServices_DID_D005_High_Quiescent_Current_Fault_Identification_Data_DID_D005_3st_System_Global_Time_the_time_when_th_75ED068F: required-interface=DataServices_DID_D005_High_Quiescent_Current_Fault_Identification_Data_DID_D005_3st_System_Global_Time_the_time_when_th_75ED068F
      DataServices_DID_D005_High_Quiescent_Current_Fault_Identification_Data_D005_3st_Functionality_Activity_Level_PNC30: required-interface=DataServices_DID_D005_High_Quiescent_Current_Fault_Identification_Data_D005_3st_Functionality_Activity_Level_PNC30
      DataServices_DID_D005_High_Quiescent_Current_Fault_Identification_Data_Reserved_Data_Field_2st: required-interface=DataServices_DID_D005_High_Quiescent_Current_Fault_Identification_Data_Reserved_Data_Field_2st
      DataServices_DID_D005_High_Quiescent_Current_Fault_Identification_Data_DID_D005_2st_Global_time_when_Functionality_Acti_75CD35A0: required-interface=DataServices_DID_D005_High_Quiescent_Current_Fault_Identification_Data_DID_D005_2st_Global_time_when_Functionality_Acti_75CD35A0
      DataServices_DID_D005_High_Quiescent_Current_Fault_Identification_Data_D005_3st_Functionality_Activity_Level_PNC25: required-interface=DataServices_DID_D005_High_Quiescent_Current_Fault_Identification_Data_D005_3st_Functionality_Activity_Level_PNC25
      DataServices_DID_D005_High_Quiescent_Current_Fault_Identification_Data_D005_3st_Functionality_Activity_Level_PNC24: required-interface=DataServices_DID_D005_High_Quiescent_Current_Fault_Identification_Data_D005_3st_Functionality_Activity_Level_PNC24
      DataServices_DID_D005_High_Quiescent_Current_Fault_Identification_Data_D005_3st_Functionality_Activity_Level_PNC27: required-interface=DataServices_DID_D005_High_Quiescent_Current_Fault_Identification_Data_D005_3st_Functionality_Activity_Level_PNC27
      DataServices_DID_D005_High_Quiescent_Current_Fault_Identification_Data_D005_3st_Functionality_Activity_Level_PNC26: required-interface=DataServices_DID_D005_High_Quiescent_Current_Fault_Identification_Data_D005_3st_Functionality_Activity_Level_PNC26
      DataServices_DID_D005_High_Quiescent_Current_Fault_Identification_Data_D005_5st_Functionality_Activity_Level_PNC39: required-interface=DataServices_DID_D005_High_Quiescent_Current_Fault_Identification_Data_D005_5st_Functionality_Activity_Level_PNC39
      DataServices_DID_D005_High_Quiescent_Current_Fault_Identification_Data_D005_3st_Functionality_Activity_Level_PNC29: required-interface=DataServices_DID_D005_High_Quiescent_Current_Fault_Identification_Data_D005_3st_Functionality_Activity_Level_PNC29
      DataServices_DID_D005_High_Quiescent_Current_Fault_Identification_Data_DID_D005_1_1st_System_Global_Time_the_time_when_2A73953F: required-interface=DataServices_DID_D005_High_Quiescent_Current_Fault_Identification_Data_DID_D005_1_1st_System_Global_Time_the_time_when_2A73953F
      DataServices_DID_D005_High_Quiescent_Current_Fault_Identification_Data_D005_2st_Functionality_Activity_Level_PNC29: required-interface=DataServices_DID_D005_High_Quiescent_Current_Fault_Identification_Data_D005_2st_Functionality_Activity_Level_PNC29
      DataServices_DID_D005_High_Quiescent_Current_Fault_Identification_Data_Functionality_Activity_Level_Detect_DC_Bus_volta_2AFD28A9: required-interface=DataServices_DID_D005_High_Quiescent_Current_Fault_Identification_Data_Functionality_Activity_Level_Detect_DC_Bus_volta_2AFD28A9
      DataServices_DID_D005_High_Quiescent_Current_Fault_Identification_Data_D005_4st_Functionality_Activity_Level_PNC35: required-interface=DataServices_DID_D005_High_Quiescent_Current_Fault_Identification_Data_D005_4st_Functionality_Activity_Level_PNC35
      DataServices_DID_D005_High_Quiescent_Current_Fault_Identification_Data_D005_2st_Functionality_Activity_Level_PNC27: required-interface=DataServices_DID_D005_High_Quiescent_Current_Fault_Identification_Data_D005_2st_Functionality_Activity_Level_PNC27
      DataServices_DID_D005_High_Quiescent_Current_Fault_Identification_Data_DID_D005_4st_System_Global_Time_the_time_when_th_9B810F90: required-interface=DataServices_DID_D005_High_Quiescent_Current_Fault_Identification_Data_DID_D005_4st_System_Global_Time_the_time_when_th_9B810F90
      DataServices_DID_D005_High_Quiescent_Current_Fault_Identification_Data_D005_2st_Functionality_Activity_Level_PNC26: required-interface=DataServices_DID_D005_High_Quiescent_Current_Fault_Identification_Data_D005_2st_Functionality_Activity_Level_PNC26
      DataServices_DID_D005_High_Quiescent_Current_Fault_Identification_Data_D005_2st_Functionality_Activity_Level_PNC25: required-interface=DataServices_DID_D005_High_Quiescent_Current_Fault_Identification_Data_D005_2st_Functionality_Activity_Level_PNC25
      DataServices_DID_D005_High_Quiescent_Current_Fault_Identification_Data_D005_4st_Functionality_Activity_Level_PNC30: required-interface=DataServices_DID_D005_High_Quiescent_Current_Fault_Identification_Data_D005_4st_Functionality_Activity_Level_PNC30
      DataServices_DID_D005_High_Quiescent_Current_Fault_Identification_Data_D005_2st_Functionality_Activity_Level_PNC24: required-interface=DataServices_DID_D005_High_Quiescent_Current_Fault_Identification_Data_D005_2st_Functionality_Activity_Level_PNC24
      DataServices_DID_D005_High_Quiescent_Current_Fault_Identification_Data_DID_D005_3st_Global_time_when_Functionality_Acti_A45DA93A: required-interface=DataServices_DID_D005_High_Quiescent_Current_Fault_Identification_Data_DID_D005_3st_Global_time_when_Functionality_Acti_A45DA93A
      DataServices_DID_D005_High_Quiescent_Current_Fault_Identification_Data_D005_5st_Functionality_Activity_Level_PNC35: required-interface=DataServices_DID_D005_High_Quiescent_Current_Fault_Identification_Data_D005_5st_Functionality_Activity_Level_PNC35
      DataServices_DID_D005_High_Quiescent_Current_Fault_Identification_Data_Bitfield_3th: required-interface=DataServices_DID_D005_High_Quiescent_Current_Fault_Identification_Data_Bitfield_3th
      DataServices_DID_D005_High_Quiescent_Current_Fault_Identification_Data_DID_D005_2st_System_Global_Time_the_time_when_th_5058FD8E: required-interface=DataServices_DID_D005_High_Quiescent_Current_Fault_Identification_Data_DID_D005_2st_System_Global_Time_the_time_when_th_5058FD8E
      DataServices_DID_D005_High_Quiescent_Current_Fault_Identification_Data_Functionality_Activity_Level_Detect_CPSR_Keep_Active_1st: required-interface=DataServices_DID_D005_High_Quiescent_Current_Fault_Identification_Data_Functionality_Activity_Level_Detect_CPSR_Keep_Active_1st
      DataServices_DID_D005_High_Quiescent_Current_Fault_Identification_Data_Bitfield_1th: required-interface=DataServices_DID_D005_High_Quiescent_Current_Fault_Identification_Data_Bitfield_1th
      DataServices_DID_D005_High_Quiescent_Current_Fault_Identification_Data_DID_D005_3st_Usage_Mode_when_DID_is_triggered: required-interface=DataServices_DID_D005_High_Quiescent_Current_Fault_Identification_Data_DID_D005_3st_Usage_Mode_when_DID_is_triggered
      DataServices_DID_D005_High_Quiescent_Current_Fault_Identification_Data_D005_5st_Functionality_Activity_Level_PNC30: required-interface=DataServices_DID_D005_High_Quiescent_Current_Fault_Identification_Data_D005_5st_Functionality_Activity_Level_PNC30
      DataServices_DID_D005_High_Quiescent_Current_Fault_Identification_Data_D005_3st_Functionality_Activity_Level_PNC35: required-interface=DataServices_DID_D005_High_Quiescent_Current_Fault_Identification_Data_D005_3st_Functionality_Activity_Level_PNC35
      DataServices_DID_D005_High_Quiescent_Current_Fault_Identification_Data_Reserved_PNC_1st: required-interface=DataServices_DID_D005_High_Quiescent_Current_Fault_Identification_Data_Reserved_PNC_1st
      DataServices_DID_D005_High_Quiescent_Current_Fault_Identification_Data_DID_D005_4st_Global_time_when_Functionality_Acti_F1BD651E: required-interface=DataServices_DID_D005_High_Quiescent_Current_Fault_Identification_Data_DID_D005_4st_Global_time_when_Functionality_Acti_F1BD651E
      DataServices_DID_D005_High_Quiescent_Current_Fault_Identification_Data_Functionality_Activity_Level_Detect_CPSR_Keep_Active_3st: required-interface=DataServices_DID_D005_High_Quiescent_Current_Fault_Identification_Data_Functionality_Activity_Level_Detect_CPSR_Keep_Active_3st
      DataServices_DID_D005_High_Quiescent_Current_Fault_Identification_Data_Reserved_PNC_5st: required-interface=DataServices_DID_D005_High_Quiescent_Current_Fault_Identification_Data_Reserved_PNC_5st
      DataServices_DID_D005_High_Quiescent_Current_Fault_Identification_Data_D005_5st_Functionality_Activity_Level_PNC29: required-interface=DataServices_DID_D005_High_Quiescent_Current_Fault_Identification_Data_D005_5st_Functionality_Activity_Level_PNC29
      DataServices_DID_D005_High_Quiescent_Current_Fault_Identification_Data_Functionality_Activity_Level_Detect_DC_Bus_volta_BF51DF82: required-interface=DataServices_DID_D005_High_Quiescent_Current_Fault_Identification_Data_Functionality_Activity_Level_Detect_DC_Bus_volta_BF51DF82
      DataServices_DID_D005_High_Quiescent_Current_Fault_Identification_Data_D005_3st_Functionality_Activity_Level_PNC39: required-interface=DataServices_DID_D005_High_Quiescent_Current_Fault_Identification_Data_D005_3st_Functionality_Activity_Level_PNC39
      DataServices_DID_D005_High_Quiescent_Current_Fault_Identification_Data_Functionality_Activity_Level_Detect_CPSR_Keep_Active_5st: required-interface=DataServices_DID_D005_High_Quiescent_Current_Fault_Identification_Data_Functionality_Activity_Level_Detect_CPSR_Keep_Active_5st
      DataServices_DID_D005_High_Quiescent_Current_Fault_Identification_Data_D005_5st_Functionality_Activity_Level_PNC26: required-interface=DataServices_DID_D005_High_Quiescent_Current_Fault_Identification_Data_D005_5st_Functionality_Activity_Level_PNC26
      DataServices_DID_D005_High_Quiescent_Current_Fault_Identification_Data_D005_5st_Functionality_Activity_Level_PNC27: required-interface=DataServices_DID_D005_High_Quiescent_Current_Fault_Identification_Data_D005_5st_Functionality_Activity_Level_PNC27
      DataServices_DID_D005_High_Quiescent_Current_Fault_Identification_Data_Reserved_PNC_3st: required-interface=DataServices_DID_D005_High_Quiescent_Current_Fault_Identification_Data_Reserved_PNC_3st
      DataServices_DID_D005_High_Quiescent_Current_Fault_Identification_Data_D005_4st_Functionality_Activity_Level_PNC24: required-interface=DataServices_DID_D005_High_Quiescent_Current_Fault_Identification_Data_D005_4st_Functionality_Activity_Level_PNC24
      DataServices_DID_D005_High_Quiescent_Current_Fault_Identification_Data_Functionality_Activity_Level_Detect_Motor_Speed_AE736296: required-interface=DataServices_DID_D005_High_Quiescent_Current_Fault_Identification_Data_Functionality_Activity_Level_Detect_Motor_Speed_AE736296
      DataServices_DID_D005_High_Quiescent_Current_Fault_Identification_Data_Functionality_Activity_Level_Detect_Motor_Speed_AE735B14: required-interface=DataServices_DID_D005_High_Quiescent_Current_Fault_Identification_Data_Functionality_Activity_Level_Detect_Motor_Speed_AE735B14
      DataServices_DID_D005_High_Quiescent_Current_Fault_Identification_Data_DID_D005_2_1st_Global_time_when_Functionality_Ac_89793B23: required-interface=DataServices_DID_D005_High_Quiescent_Current_Fault_Identification_Data_DID_D005_2_1st_Global_time_when_Functionality_Ac_89793B23
      DataServices_DID_D005_High_Quiescent_Current_Fault_Identification_Data_Reserved_Data_Field_3st: required-interface=DataServices_DID_D005_High_Quiescent_Current_Fault_Identification_Data_Reserved_Data_Field_3st
      DataServices_DID_D005_High_Quiescent_Current_Fault_Identification_Data_Functionality_Activity_Level_Detect_DC_Bus_volta_2AFD1D66: required-interface=DataServices_DID_D005_High_Quiescent_Current_Fault_Identification_Data_Functionality_Activity_Level_Detect_DC_Bus_volta_2AFD1D66
      DataServices_DID_D005_High_Quiescent_Current_Fault_Identification_Data_Reserved_Data_Field_5st: required-interface=DataServices_DID_D005_High_Quiescent_Current_Fault_Identification_Data_Reserved_Data_Field_5st
      DataServices_DID_D005_High_Quiescent_Current_Fault_Identification_Data_D005_5st_Functionality_Activity_Level_PNC24: required-interface=DataServices_DID_D005_High_Quiescent_Current_Fault_Identification_Data_D005_5st_Functionality_Activity_Level_PNC24
      DataServices_DID_D005_High_Quiescent_Current_Fault_Identification_Data_D005_5st_Functionality_Activity_Level_PNC25: required-interface=DataServices_DID_D005_High_Quiescent_Current_Fault_Identification_Data_D005_5st_Functionality_Activity_Level_PNC25
      DataServices_DID_D005_High_Quiescent_Current_Fault_Identification_Data_Reserved_Data_Field_1st: required-interface=DataServices_DID_D005_High_Quiescent_Current_Fault_Identification_Data_Reserved_Data_Field_1st
      DataServices_DID_D005_High_Quiescent_Current_Fault_Identification_Data_D005_1st_Functionality_Activity_Level_PNC39: required-interface=DataServices_DID_D005_High_Quiescent_Current_Fault_Identification_Data_D005_1st_Functionality_Activity_Level_PNC39
      DataServices_DID_D005_High_Quiescent_Current_Fault_Identification_Data_D005_1st_Functionality_Activity_Level_PNC35: required-interface=DataServices_DID_D005_High_Quiescent_Current_Fault_Identification_Data_D005_1st_Functionality_Activity_Level_PNC35
      DataServices_DID_D005_High_Quiescent_Current_Fault_Identification_Data_DID_D005_4st_Usage_Mode_when_DID_is_triggered: required-interface=DataServices_DID_D005_High_Quiescent_Current_Fault_Identification_Data_DID_D005_4st_Usage_Mode_when_DID_is_triggered
      DataServices_DID_D005_High_Quiescent_Current_Fault_Identification_Data_Bitfield_5th: required-interface=DataServices_DID_D005_High_Quiescent_Current_Fault_Identification_Data_Bitfield_5th
      DataServices_DID_D005_High_Quiescent_Current_Fault_Identification_Data_Functionality_Activity_Level_Detect_DC_Bus_volta_2AFD24E8: required-interface=DataServices_DID_D005_High_Quiescent_Current_Fault_Identification_Data_Functionality_Activity_Level_Detect_DC_Bus_volta_2AFD24E8
      DataServices_DID_40E0_Secret_Key_Immobilizer_Target_3_DID_40DF_Secret_Key_Immobilizer_Target_2: required-interface=DataServices_DID_40E0_Secret_Key_Immobilizer_Target_3_DID_40DF_Secret_Key_Immobilizer_Target_2
      DataServices_DID_EEB8_HV_voltage_received_from_BECM_DID_EEB8_HV_voltage_received_from_BECM: required-interface=DataServices_DID_EEB8_HV_voltage_received_from_BECM_DID_EEB8_HV_voltage_received_from_BECM
      DataServices_DID_E348_Phase_U_PWM_duty_DID_E348_Phase_U_PWM_duty: required-interface=DataServices_DID_E348_Phase_U_PWM_duty_DID_E348_Phase_U_PWM_duty
      DataServices_DID_D211_Network_Management_History_Propulsion_CAN_DID_D211_20_10th_Latest_State_Global_Real_Time: required-interface=DataServices_DID_D211_Network_Management_History_Propulsion_CAN_DID_D211_20_10th_Latest_State_Global_Real_Time
      DataServices_DID_D211_Network_Management_History_Propulsion_CAN_DID_D211_1_Latest_State_NM_History: required-interface=DataServices_DID_D211_Network_Management_History_Propulsion_CAN_DID_D211_1_Latest_State_NM_History
      DataServices_DID_D211_Network_Management_History_Propulsion_CAN_DID_D211_16_8th_Latest_State_Global_Real_Time: required-interface=DataServices_DID_D211_Network_Management_History_Propulsion_CAN_DID_D211_16_8th_Latest_State_Global_Real_Time
      DataServices_DID_D211_Network_Management_History_Propulsion_CAN_DID_D211_11_6th_Latest_State_NM_History: required-interface=DataServices_DID_D211_Network_Management_History_Propulsion_CAN_DID_D211_11_6th_Latest_State_NM_History
      DataServices_DID_D211_Network_Management_History_Propulsion_CAN_DID_D211_4_2nd_Latest_State_Global_Real_Time: required-interface=DataServices_DID_D211_Network_Management_History_Propulsion_CAN_DID_D211_4_2nd_Latest_State_Global_Real_Time
      DataServices_DID_D211_Network_Management_History_Propulsion_CAN_DID_D211_2_Latest_State_Global_Real_Time: required-interface=DataServices_DID_D211_Network_Management_History_Propulsion_CAN_DID_D211_2_Latest_State_Global_Real_Time
      DataServices_DID_D211_Network_Management_History_Propulsion_CAN_DID_D211_12_6th_Latest_State_Global_Real_Time: required-interface=DataServices_DID_D211_Network_Management_History_Propulsion_CAN_DID_D211_12_6th_Latest_State_Global_Real_Time
      DataServices_DID_D211_Network_Management_History_Propulsion_CAN_DID_D211_5_3rd_Latest_State_NM_History: required-interface=DataServices_DID_D211_Network_Management_History_Propulsion_CAN_DID_D211_5_3rd_Latest_State_NM_History
      DataServices_DID_D211_Network_Management_History_Propulsion_CAN_DID_D211_17_9th_Latest_State_NM_History: required-interface=DataServices_DID_D211_Network_Management_History_Propulsion_CAN_DID_D211_17_9th_Latest_State_NM_History
      DataServices_DID_D211_Network_Management_History_Propulsion_CAN_DID_D211_9_5th_Latest_State_NM_History: required-interface=DataServices_DID_D211_Network_Management_History_Propulsion_CAN_DID_D211_9_5th_Latest_State_NM_History
      DataServices_DID_D211_Network_Management_History_Propulsion_CAN_DID_D211_13_7th_Latest_State_NM_History: required-interface=DataServices_DID_D211_Network_Management_History_Propulsion_CAN_DID_D211_13_7th_Latest_State_NM_History
      DataServices_DID_D211_Network_Management_History_Propulsion_CAN_DID_D211_8_4th_Latest_State_Global_Real_Time: required-interface=DataServices_DID_D211_Network_Management_History_Propulsion_CAN_DID_D211_8_4th_Latest_State_Global_Real_Time
      DataServices_DID_D211_Network_Management_History_Propulsion_CAN_DID_D211_10_5th_Latest_State_Global_Real_Time: required-interface=DataServices_DID_D211_Network_Management_History_Propulsion_CAN_DID_D211_10_5th_Latest_State_Global_Real_Time
      DataServices_DID_D211_Network_Management_History_Propulsion_CAN_DID_D211_18_9th_Latest_State_Global_Real_Time: required-interface=DataServices_DID_D211_Network_Management_History_Propulsion_CAN_DID_D211_18_9th_Latest_State_Global_Real_Time
      DataServices_DID_D211_Network_Management_History_Propulsion_CAN_DID_D211_6_3rd_Latest_State_Global_Real_Time: required-interface=DataServices_DID_D211_Network_Management_History_Propulsion_CAN_DID_D211_6_3rd_Latest_State_Global_Real_Time
      DataServices_DID_D211_Network_Management_History_Propulsion_CAN_DID_D211_15_8th_Latest_State_NM_History: required-interface=DataServices_DID_D211_Network_Management_History_Propulsion_CAN_DID_D211_15_8th_Latest_State_NM_History
      DataServices_DID_D211_Network_Management_History_Propulsion_CAN_DID_D211_19_10th_Latest_State_NM_History: required-interface=DataServices_DID_D211_Network_Management_History_Propulsion_CAN_DID_D211_19_10th_Latest_State_NM_History
      DataServices_DID_D211_Network_Management_History_Propulsion_CAN_DID_D211_14_7th_Latest_State_Global_Real_Time: required-interface=DataServices_DID_D211_Network_Management_History_Propulsion_CAN_DID_D211_14_7th_Latest_State_Global_Real_Time
      DataServices_DID_D211_Network_Management_History_Propulsion_CAN_DID_D211_3_2nd_Latest_State_NM_History: required-interface=DataServices_DID_D211_Network_Management_History_Propulsion_CAN_DID_D211_3_2nd_Latest_State_NM_History
      DataServices_DID_D211_Network_Management_History_Propulsion_CAN_DID_D211_7_4th_Latest_State_NM_History: required-interface=DataServices_DID_D211_Network_Management_History_Propulsion_CAN_DID_D211_7_4th_Latest_State_NM_History
      DataServices_DID_E303_Motor_Speed_DID_E303_Motor_Speed_: required-interface=DataServices_DID_E303_Motor_Speed_DID_E303_Motor_Speed_
      DataServices_DID_E324_Motor_Derating_reason_of_IEM_MGM_DID_E324_Motor_Derating_reason_of_IEMMGM: required-interface=DataServices_DID_E324_Motor_Derating_reason_of_IEM_MGM_DID_E324_Motor_Derating_reason_of_IEMMGM
      DataServices_DID_DD01_Total_Distance_DID_DD01_Total_Distance: required-interface=DataServices_DID_DD01_Total_Distance_DID_DD01_Total_Distance
      DataServices_DID_E320_System_Mode_Mismatch_DID_E320_System_Mode_Mismatch: required-interface=DataServices_DID_E320_System_Mode_Mismatch_DID_E320_System_Mode_Mismatch
      DataServices_DID_F12F_ECU_Software_Extended_Part_Numbers_ASCII_part_009: required-interface=DataServices_DID_F12F_ECU_Software_Extended_Part_Numbers_ASCII_part_009
      DataServices_DID_F12F_ECU_Software_Extended_Part_Numbers_BCD_part_005: required-interface=DataServices_DID_F12F_ECU_Software_Extended_Part_Numbers_BCD_part_005
      DataServices_DID_F12F_ECU_Software_Extended_Part_Numbers_BCD_part_006: required-interface=DataServices_DID_F12F_ECU_Software_Extended_Part_Numbers_BCD_part_006
      DataServices_DID_F12F_ECU_Software_Extended_Part_Numbers_BCD_part_003: required-interface=DataServices_DID_F12F_ECU_Software_Extended_Part_Numbers_BCD_part_003
      DataServices_DID_F12F_ECU_Software_Extended_Part_Numbers_BCD_part_004: required-interface=DataServices_DID_F12F_ECU_Software_Extended_Part_Numbers_BCD_part_004
      DataServices_DID_F12F_ECU_Software_Extended_Part_Numbers_ASCII_part_005: required-interface=DataServices_DID_F12F_ECU_Software_Extended_Part_Numbers_ASCII_part_005
      DataServices_DID_F12F_ECU_Software_Extended_Part_Numbers_BCD_part_001: required-interface=DataServices_DID_F12F_ECU_Software_Extended_Part_Numbers_BCD_part_001
      DataServices_DID_F12F_ECU_Software_Extended_Part_Numbers_ASCII_part_006: required-interface=DataServices_DID_F12F_ECU_Software_Extended_Part_Numbers_ASCII_part_006
      DataServices_DID_F12F_ECU_Software_Extended_Part_Numbers_BCD_part_002: required-interface=DataServices_DID_F12F_ECU_Software_Extended_Part_Numbers_BCD_part_002
      DataServices_DID_F12F_ECU_Software_Extended_Part_Numbers_ASCII_part_007: required-interface=DataServices_DID_F12F_ECU_Software_Extended_Part_Numbers_ASCII_part_007
      DataServices_DID_F12F_ECU_Software_Extended_Part_Numbers_ASCII_part_008: required-interface=DataServices_DID_F12F_ECU_Software_Extended_Part_Numbers_ASCII_part_008
      DataServices_DID_F12F_ECU_Software_Extended_Part_Numbers_BCD_part: required-interface=DataServices_DID_F12F_ECU_Software_Extended_Part_Numbers_BCD_part
      DataServices_DID_F12F_ECU_Software_Extended_Part_Numbers_DID_F12F_1_Total_number_of_ECU_Software_Part_Numbers: required-interface=DataServices_DID_F12F_ECU_Software_Extended_Part_Numbers_DID_F12F_1_Total_number_of_ECU_Software_Part_Numbers
      DataServices_DID_F12F_ECU_Software_Extended_Part_Numbers_ASCII_part_{001..004}: required-interface=DataServices_DID_F12F_ECU_Software_Extended_Part_Numbers_ASCII_part_{001..004}
      DataServices_DID_F12F_ECU_Software_Extended_Part_Numbers_ASCII_part: required-interface=DataServices_DID_F12F_ECU_Software_Extended_Part_Numbers_ASCII_part
      DataServices_DID_F12F_ECU_Software_Extended_Part_Numbers_BCD_part_009: required-interface=DataServices_DID_F12F_ECU_Software_Extended_Part_Numbers_BCD_part_009
      DataServices_DID_F12F_ECU_Software_Extended_Part_Numbers_BCD_part_007: required-interface=DataServices_DID_F12F_ECU_Software_Extended_Part_Numbers_BCD_part_007
      DataServices_DID_F12F_ECU_Software_Extended_Part_Numbers_BCD_part_008: required-interface=DataServices_DID_F12F_ECU_Software_Extended_Part_Numbers_BCD_part_008
      DataServices_DID_EEC4_Charging_Power_Sustain_Relay_CPSR_Voltage_DID_EEC4_Charging_Power_Sustain_RelayCPSR_Voltage: required-interface=DataServices_DID_EEC4_Charging_Power_Sustain_Relay_CPSR_Voltage_DID_EEC4_Charging_Power_Sustain_RelayCPSR_Voltage
      DataServices_DID_F12B_ECU_Delivery_Assembly_Part_Number_ASCII_part: required-interface=DataServices_DID_F12B_ECU_Delivery_Assembly_Part_Number_ASCII_part
      DataServices_DID_F12B_ECU_Delivery_Assembly_Part_Number_BCD_part: required-interface=DataServices_DID_F12B_ECU_Delivery_Assembly_Part_Number_BCD_part
      DataServices_DID_F12A_ECU_Core_Assembly_Part_Number_ASCII_part: required-interface=DataServices_DID_F12A_ECU_Core_Assembly_Part_Number_ASCII_part
      DataServices_DID_F12A_ECU_Core_Assembly_Part_Number_BCD_part: required-interface=DataServices_DID_F12A_ECU_Core_Assembly_Part_Number_BCD_part
      DataServices_DID_E346_ECM_Torque_Allowed_Status_DID_E346_ECM_Torque_Allowed_Status: required-interface=DataServices_DID_E346_ECM_Torque_Allowed_Status_DID_E346_ECM_Torque_Allowed_Status
      DataServices_DID_EED3_Safety_speed_DID_EED3_Safety_speed: required-interface=DataServices_DID_EED3_Safety_speed_DID_EED3_Safety_speed
      DataServices_DID_DD0C_Electric_Power_Level_DID_DD0C_Electric_Power_Level: required-interface=DataServices_DID_DD0C_Electric_Power_Level_DID_DD0C_Electric_Power_Level
      DataServices_DID_F1A0_Application_Diagnostic_Database_Part_Number_Geely_ASCII_part: required-interface=DataServices_DID_F1A0_Application_Diagnostic_Database_Part_Number_Geely_ASCII_part
      DataServices_DID_F1A0_Application_Diagnostic_Database_Part_Number_Geely_BCD_part: required-interface=DataServices_DID_F1A0_Application_Diagnostic_Database_Part_Number_Geely_BCD_part
      DataServices_DID_E309_ECM_Mode_Request_DID_E309_ECM_Mode_Request: required-interface=DataServices_DID_E309_ECM_Mode_Request_DID_E309_ECM_Mode_Request
      DataServices_DID_E103_Car_Configuration_Parameter_Faults_DID_E103_3_1st_parameter_invalid_value: required-interface=DataServices_DID_E103_Car_Configuration_Parameter_Faults_DID_E103_3_1st_parameter_invalid_value
      DataServices_DID_E103_Car_Configuration_Parameter_Faults_DID_E103_1_Number_of_invalid_car_configuration_parameter_value_7E36D2F5: required-interface=DataServices_DID_E103_Car_Configuration_Parameter_Faults_DID_E103_1_Number_of_invalid_car_configuration_parameter_value_7E36D2F5
      DataServices_DID_E103_Car_Configuration_Parameter_Faults_DID_E103_21_10th_parameter_invalid_value: required-interface=DataServices_DID_E103_Car_Configuration_Parameter_Faults_DID_E103_21_10th_parameter_invalid_value
      DataServices_DID_E103_Car_Configuration_Parameter_Faults_DID_E103_20_10th_parameter_number_of_the_car_configuration_dat_86F3B3DF: required-interface=DataServices_DID_E103_Car_Configuration_Parameter_Faults_DID_E103_20_10th_parameter_number_of_the_car_configuration_dat_86F3B3DF
      DataServices_DID_E103_Car_Configuration_Parameter_Faults_DID_E103_16_8th_parameter_number_of_the_car_configuration_data_2E2F0597: required-interface=DataServices_DID_E103_Car_Configuration_Parameter_Faults_DID_E103_16_8th_parameter_number_of_the_car_configuration_data_2E2F0597
      DataServices_DID_E103_Car_Configuration_Parameter_Faults_DID_E103_12_6th_parameter_number_of_the_car_configuration_data_E81803DD: required-interface=DataServices_DID_E103_Car_Configuration_Parameter_Faults_DID_E103_12_6th_parameter_number_of_the_car_configuration_data_E81803DD
      DataServices_DID_E103_Car_Configuration_Parameter_Faults_DID_E103_11_5th_parameter_invalid_value: required-interface=DataServices_DID_E103_Car_Configuration_Parameter_Faults_DID_E103_11_5th_parameter_invalid_value
      DataServices_DID_E103_Car_Configuration_Parameter_Faults_DID_E103_15_7th_parameter_invalid_value: required-interface=DataServices_DID_E103_Car_Configuration_Parameter_Faults_DID_E103_15_7th_parameter_invalid_value
      DataServices_DID_E103_Car_Configuration_Parameter_Faults_DID_E103_6_3rd_parameter_number_of_the_car_configuration_data_DA502437: required-interface=DataServices_DID_E103_Car_Configuration_Parameter_Faults_DID_E103_6_3rd_parameter_number_of_the_car_configuration_data_DA502437
      DataServices_DID_E103_Car_Configuration_Parameter_Faults_DID_E103_10_5th_parameter_number_of_the_car_configuration_data_450C8300: required-interface=DataServices_DID_E103_Car_Configuration_Parameter_Faults_DID_E103_10_5th_parameter_number_of_the_car_configuration_data_450C8300
      DataServices_DID_E103_Car_Configuration_Parameter_Faults_DID_E103_8_4th_parameter_number_of_the_car_configuration_data_125EA492: required-interface=DataServices_DID_E103_Car_Configuration_Parameter_Faults_DID_E103_8_4th_parameter_number_of_the_car_configuration_data_125EA492
      DataServices_DID_E103_Car_Configuration_Parameter_Faults_DID_E103_5_2nd_parameter_invalid_value: required-interface=DataServices_DID_E103_Car_Configuration_Parameter_Faults_DID_E103_5_2nd_parameter_invalid_value
      DataServices_DID_E103_Car_Configuration_Parameter_Faults_DID_E103_18_9th_parameter_number_of_the_car_configuration_data_D13A8674: required-interface=DataServices_DID_E103_Car_Configuration_Parameter_Faults_DID_E103_18_9th_parameter_number_of_the_car_configuration_data_D13A8674
      DataServices_DID_E103_Car_Configuration_Parameter_Faults_DID_E103_4_2nd_parameter_number_of_the_car_configuration_data_0046C356: required-interface=DataServices_DID_E103_Car_Configuration_Parameter_Faults_DID_E103_4_2nd_parameter_number_of_the_car_configuration_data_0046C356
      DataServices_DID_E103_Car_Configuration_Parameter_Faults_DID_E103_14_7th_parameter_number_of_the_car_configuration_data_8B2384BA: required-interface=DataServices_DID_E103_Car_Configuration_Parameter_Faults_DID_E103_14_7th_parameter_number_of_the_car_configuration_data_8B2384BA
      DataServices_DID_E103_Car_Configuration_Parameter_Faults_DID_E103_19_9th_parameter_invalid_value: required-interface=DataServices_DID_E103_Car_Configuration_Parameter_Faults_DID_E103_19_9th_parameter_invalid_value
      DataServices_DID_E103_Car_Configuration_Parameter_Faults_DID_E103_9_4th_parameter_invalid_value: required-interface=DataServices_DID_E103_Car_Configuration_Parameter_Faults_DID_E103_9_4th_parameter_invalid_value
      DataServices_DID_E103_Car_Configuration_Parameter_Faults_DID_E103_17_8th_parameter_invalid_value: required-interface=DataServices_DID_E103_Car_Configuration_Parameter_Faults_DID_E103_17_8th_parameter_invalid_value
      DataServices_DID_E103_Car_Configuration_Parameter_Faults_DID_E103_13_6th_parameter_invalid_value: required-interface=DataServices_DID_E103_Car_Configuration_Parameter_Faults_DID_E103_13_6th_parameter_invalid_value
      DataServices_DID_E103_Car_Configuration_Parameter_Faults_DID_E103_2_1st_parameter_number_of_the_car_configuration_data_C808D86E: required-interface=DataServices_DID_E103_Car_Configuration_Parameter_Faults_DID_E103_2_1st_parameter_number_of_the_car_configuration_data_C808D86E
      DataServices_DID_E103_Car_Configuration_Parameter_Faults_DID_E103_7_3rd_parameter_invalid_value: required-interface=DataServices_DID_E103_Car_Configuration_Parameter_Faults_DID_E103_7_3rd_parameter_invalid_value
      DataServices_DID_E311_Crash_Status_DID_E311_Crash_Status: required-interface=DataServices_DID_E311_Crash_Status_DID_E311_Crash_Status
      DataServices_DID_EEC5_ImobEng2_node_status_DID_EEC5_ImobEng2_node_status: required-interface=DataServices_DID_EEC5_ImobEng2_node_status_DID_EEC5_ImobEng2_node_status
      DataServices_DID_EF0A_Active_Discharge_Time_DID_EF0A_Active_Discharge_Time: required-interface=DataServices_DID_EF0A_Active_Discharge_Time_DID_EF0A_Active_Discharge_Time
      Dcm: required-interface=DcmIf
    behavior DcmInternalBehavior: data-type-mapping=DcmMappingSet, handle-termination-and-restart=NO-SUPPORT, included-data-type-set=data-type=[Dcm_ConfirmationStatusType, Dcm_OpStatusType, Dcm_NegativeResponseCodeType, Dcm_ProtocolType, Dcm_RequestKindType, Dcm_SecLevelType, Dcm_SesCtrlType, Dcm_EcuResetType, Dcm_DiagnosticSessionControlType, Dcm_CommunicationModeType]
      timing event Timer_Dcm_MainFunction: start-on-event=Dcm_MainFunction, period=0.01
      6 x operation invoked event:
        OpEventGetActiveProtocol_GetActiveProtocol_DCMServices: start-on-event=GetActiveProtocol, operation=DCMServices.GetActiveProtocol
        OpEventGetSesCtrlType_GetSesCtrlType_DCMServices: start-on-event=GetSesCtrlType, operation=DCMServices.GetSesCtrlType
        OpEventResetToDefaultSession_ResetToDefaultSession_DCMServices: start-on-event=ResetToDefaultSession, operation=DCMServices.ResetToDefaultSession
        OpEventGetSecurityLevel_GetSecurityLevel_DCMServices: start-on-event=GetSecurityLevel, operation=DCMServices.GetSecurityLevel
        OpEventSetActiveDiagnostic_SetActiveDiagnostic_DCMServices: start-on-event=SetActiveDiagnostic, operation=DCMServices.SetActiveDiagnostic
        OpEventGetRequestKind_GetRequestKind_DCMServices: start-on-event=GetRequestKind, operation=DCMServices.GetRequestKind
      port-api-options:
        enable-take-address=true, indirect-api=false, port=DcmEcuReset
        enable-take-address=true, indirect-api=false, port=DcmDiagnosticSessionControl
        enable-take-address=true, indirect-api=false, port=DCMServices
        enable-take-address=true, indirect-api=false, port=SecurityAccess_CommonUnlock_Level_3
        enable-take-address=true, indirect-api=false, port=SecurityAccess_ImmoUnlocked_Level_4
        enable-take-address=true, indirect-api=false, port=RoutineServices_Check_programming_pre_conditions
        enable-take-address=true, indirect-api=false, port=RoutineServices_P_Lock
        enable-take-address=true, indirect-api=false, port=RoutineServices_Starter_Generator_Position_Sensors_Calibration
        enable-take-address=true, indirect-api=false, port=RoutineServices_Routine_Reserved_{1..3}
        enable-take-address=true, indirect-api=false, port=DataServices_DID_E300_HVDC_Voltage_DID_E300_HVDC_Voltage
        enable-take-address=true, indirect-api=false, port=DataServices_DID_EED5_Safety_Torque_QF_factor_EED5_Safety_Torque_Quality_factor
        enable-take-address=true, indirect-api=false, port=DataServices_DID_F1A1_Primary_Bootloader_Diagnostic_Database_Part_Number_Geely_ASCII_part
        enable-take-address=true, indirect-api=false, port=DataServices_DID_F1A1_Primary_Bootloader_Diagnostic_Database_Part_Number_Geely_BCD_part
        enable-take-address=true, indirect-api=false, port=DataServices_DID_E353_Flux_weakening_correction_factor_DID_E353_Flux_weakening_correction_factor
        enable-take-address=true, indirect-api=false, port=DataServices_DID_DD00_Global_Real_Time_DID_DD00_Global_Real_Time
        enable-take-address=true, indirect-api=false, port=DataServices_DID_F186_Active_Diagnostic_Session_DID_F186_Active_Diagnostic_Session
        enable-take-address=true, indirect-api=false, port=DataServices_DID_E319_Torque_Direction_DID_E319_Torque_Direction
        enable-take-address=true, indirect-api=false, port=DataServices_DID_E338_q_axis_current_feedback_DID_E338_q_axis_current_feedback
        enable-take-address=true, indirect-api=false, port=DataServices_DID_E308_ECM_Torque_Request_DID_E308_ECM_Torque_Request
        enable-take-address=true, indirect-api=false, port=DataServices_DID_F1A5_Primary_Bootloader_Software_Part_Number_Geely_ASCII_part
        enable-take-address=true, indirect-api=false, port=DataServices_DID_F1A5_Primary_Bootloader_Software_Part_Number_Geely_BCD_part
        enable-take-address=true, indirect-api=false, port=DataServices_DID_EF1D_EOL_config_word_C_DID_EF1D_EOL_config_word_C
        enable-take-address=true, indirect-api=false, port=DataServices_DID_DD0A_Usage_Mode_DID_DD0A_Usage_Mode
        enable-take-address=true, indirect-api=false, port=DataServices_DID_D003_Vehicle_Speed_DID_D003_Vehicle_Speed
        enable-take-address=true, indirect-api=false, port=DataServices_DID_E364_AURIX_Fault_Indication_DID_E364_AURIX_Fault_Indication
        enable-take-address=true, indirect-api=false, port=DataServices_DID_F18C_ECU_Serial_Number_DID_F18C_ECU_Serial_Number
        enable-take-address=true, indirect-api=false, port=DataServices_DID_D09A_High_Quiescent_Current_Function_Activation_Deactivation_DID_D09A_High_Quiescent_Current_Function_CD3E51C5
        enable-take-address=true, indirect-api=false, port=DataServices_DID_EE9C_Transient_Phase_Current_A_DID_EE9C_Transient_Phase_Current_A
        enable-take-address=true, indirect-api=false, port=DataServices_DID_E349_Phase_V_PWM_duty_DID_E349_Phase_V_PWM_duty
        enable-take-address=true, indirect-api=false, port=DataServices_DID_E315_Available_Torque_minimum_DID_E315_Available_Torque_minimum
        enable-take-address=true, indirect-api=false, port=DataServices_DID_E314_Available_Torque_maximum_DID_E314_Available_Torque_maximum
        enable-take-address=true, indirect-api=false, port=DataServices_DID_EDA0_Complete_ECU_Part_Serial_Number_s_DID_F12E_1_Total_number_of_ECU_Software_Part_Numbers
        enable-take-address=true, indirect-api=false, port=DataServices_DID_EDA0_Complete_ECU_Part_Serial_Number_s_DID_F12A_ECU_Delivery_Assembly_Part_Number1_1
        enable-take-address=true, indirect-api=false, port=DataServices_DID_EDA0_Complete_ECU_Part_Serial_Number_s_Reserved
        enable-take-address=true, indirect-api=false, port=DataServices_DID_EDA0_Complete_ECU_Part_Serial_Number_s_DID_F12B_ECU_Delivery_Assembly_Part_Number
        enable-take-address=true, indirect-api=false, port=DataServices_DID_EDA0_Complete_ECU_Part_Serial_Number_s_DID_F18C_ECU_Serial_Number
        enable-take-address=true, indirect-api=false, port=DataServices_DID_EDA0_Complete_ECU_Part_Serial_Number_s_ASCII_part
        enable-take-address=true, indirect-api=false, port=DataServices_DID_EDA0_Complete_ECU_Part_Serial_Number_s_DID_F12B_ECU_Delivery_Assembly_Part_Number1
        enable-take-address=true, indirect-api=false, port=DataServices_DID_EDA0_Complete_ECU_Part_Serial_Number_s_F120_Application_Diagnostic_Database_Part_Number1
        enable-take-address=true, indirect-api=false, port=DataServices_DID_EDA0_Complete_ECU_Part_Serial_Number_s_F120_Application_Diagnostic_Database_Part_Number
        enable-take-address=true, indirect-api=false, port=DataServices_DID_EDA0_Complete_ECU_Part_Serial_Number_s_BCD_part
        enable-take-address=true, indirect-api=false, port=DataServices_DID_EDA0_Complete_ECU_Part_Serial_Number_s_DID_F12A_ECU_Delivery_Assembly_Part_Number_1
        enable-take-address=true, indirect-api=false, port=DataServices_DID_EED4_Safty_Function_Mode_DID_EED4_Safty_Function_Mode
        enable-take-address=true, indirect-api=false, port=DataServices_DID_EEC3_ECU_power_supply_Voltage_DID_EEC3_ECU_power_supply_Voltage
        enable-take-address=true, indirect-api=false, port=DataServices_DID_EF1B_EOL_config_word_A_DID_EF1B_EOL_config_word_A
        enable-take-address=true, indirect-api=false, port=DataServices_DID_EEBF_HV_Main_Relay_Status_DID_EEBF_HV_Main_Relay_Status
        enable-take-address=true, indirect-api=false, port=DataServices_DID_E350_Phase_W_PWM_duty_DID_E350_Phase_W_PWM_duty
        enable-take-address=true, indirect-api=false, port=DataServices_DID_F126_Autosar_BSW_Cluster_Versions_DID_F126_24_COM_CLUSTER_AR_RELEASE_REVISION_VERSION
        enable-take-address=true, indirect-api=false, port=DataServices_DID_F126_Autosar_BSW_Cluster_Versions_DID_F126_36_FLEXRAY_CLUSTER_AR_RELEASE_MAJOR_VERSION
        enable-take-address=true, indirect-api=false, port=DataServices_DID_F126_Autosar_BSW_Cluster_Versions_DID_F126_31_CAN_CLUSTER_AR_RELEASE_REVISION_VERSION
        enable-take-address=true, indirect-api=false, port=DataServices_DID_F126_Autosar_BSW_Cluster_Versions_DID_F126_26_CAN_CLUSTER_SW_MAJOR_VERSION
        enable-take-address=true, indirect-api=false, port=DataServices_DID_F126_Autosar_BSW_Cluster_Versions_DID_F126_9_DIAG_CLUSTER_VCC_DCM_VERSION
        enable-take-address=true, indirect-api=false, port=DataServices_DID_F126_Autosar_BSW_Cluster_Versions_DID_F126_40_LIN_CLUSTER_SW_MAJOR_VERSION
        enable-take-address=true, indirect-api=false, port=DataServices_DID_F126_Autosar_BSW_Cluster_Versions_DID_F126_15_MODEMGMT_CLUSTER_AR_RELEASE_MAJOR_VERSION
        enable-take-address=true, indirect-api=false, port=DataServices_DID_F126_Autosar_BSW_Cluster_Versions_DID_F126_6_DIAG_CLUSTER_AR_RELEASE_MINOR_VERSION
        enable-take-address=true, indirect-api=false, port=DataServices_DID_F126_Autosar_BSW_Cluster_Versions_DID_F126_3_DIAG_CLUSTER_SW_MINOR_VERSION
        enable-take-address=true, indirect-api=false, port=DataServices_DID_F126_Autosar_BSW_Cluster_Versions_DID_F126_8_DIAG_CLUSTER_VCC_DEM_VERSION
        enable-take-address=true, indirect-api=false, port=DataServices_DID_F126_Autosar_BSW_Cluster_Versions_DID_F126_39_LIN_CLUSTER_VENDOR_ID
        enable-take-address=true, indirect-api=false, port=DataServices_DID_F126_Autosar_BSW_Cluster_Versions_DID_F126_43_LIN_CLUSTER_AR_RELEASE_MAJOR_VERSION
        enable-take-address=true, indirect-api=false, port=DataServices_DID_F126_Autosar_BSW_Cluster_Versions_DID_F126_13_MODEMGMT_CLUSTER_SW_MINOR_VERSION
        enable-take-address=true, indirect-api=false, port=DataServices_DID_F126_Autosar_BSW_Cluster_Versions_DID_F126_23_COM_CLUSTER_AR_RELEASE_MINOR_VERSION
        enable-take-address=true, indirect-api=false, port=DataServices_DID_F126_Autosar_BSW_Cluster_Versions_DID_F126_20_COM_CLUSTER_SW_MINOR_VERSION
        enable-take-address=true, indirect-api=false, port=DataServices_DID_F126_Autosar_BSW_Cluster_Versions_DID_F126_16_MODEMGMT_CLUSTER_AR_RELEASE_MINOR_VERSION
        enable-take-address=true, indirect-api=false, port=DataServices_DID_F126_Autosar_BSW_Cluster_Versions_DID_F126_2_DIAG_CLUSTER_SW_MAJOR_VERSION
        enable-take-address=true, indirect-api=false, port=DataServices_DID_F126_Autosar_BSW_Cluster_Versions_DID_F126_35_FLEXRAY_CLUSTER_SW_PATCH_VERSION
        enable-take-address=true, indirect-api=false, port=DataServices_DID_F126_Autosar_BSW_Cluster_Versions_DID_F126_17_MODEMGMT_CLUSTER_AR_RELEASE_REVISION_VERSION
        enable-take-address=true, indirect-api=false, port=DataServices_DID_F126_Autosar_BSW_Cluster_Versions_DID_F126_4_DIAG_CLUSTER_SW_PATCH_VERSION
        enable-take-address=true, indirect-api=false, port=DataServices_DID_F126_Autosar_BSW_Cluster_Versions_DID_F126_27_CAN_CLUSTER_SW_MINOR_VERSION
        enable-take-address=true, indirect-api=false, port=DataServices_DID_F126_Autosar_BSW_Cluster_Versions_DID_F126_7_DIAG_CLUSTER_AR_RELEASE_REVISION_VERSION
        enable-take-address=true, indirect-api=false, port=DataServices_DID_F126_Autosar_BSW_Cluster_Versions_DID_F126_11_MODEMGMT_CLUSTER_VENDOR_ID
        enable-take-address=true, indirect-api=false, port=DataServices_DID_F126_Autosar_BSW_Cluster_Versions_DID_F126_34_FLEXRAY_CLUSTER_SW_MINOR_VERSION
        enable-take-address=true, indirect-api=false, port=DataServices_DID_F126_Autosar_BSW_Cluster_Versions_DID_F126_5_DIAG_CLUSTER_AR_RELEASE_MAJOR_VERSION
        enable-take-address=true, indirect-api=false, port=DataServices_DID_F126_Autosar_BSW_Cluster_Versions_DID_F126_28_CAN_CLUSTER_SW_PATCH_VERSION
        enable-take-address=true, indirect-api=false, port=DataServices_DID_F126_Autosar_BSW_Cluster_Versions_DID_F126_25_CAN_CLUSTER_VENDOR_ID
        enable-take-address=true, indirect-api=false, port=DataServices_DID_F126_Autosar_BSW_Cluster_Versions_DID_F126_42_LIN_CLUSTER_SW_PATCH_VERSION
        enable-take-address=true, indirect-api=false, port=DataServices_DID_F126_Autosar_BSW_Cluster_Versions_DID_F126_19_COM_CLUSTER_SW_MAJOR_VERSION
        enable-take-address=true, indirect-api=false, port=DataServices_DID_F126_Autosar_BSW_Cluster_Versions_DID_F126_30_CAN_CLUSTER_AR_RELEASE_MINOR_VERSION
        enable-take-address=true, indirect-api=false, port=DataServices_DID_F126_Autosar_BSW_Cluster_Versions_DID_F126_21_COM_CLUSTER_SW_PATCH_VERSION
        enable-take-address=true, indirect-api=false, port=DataServices_DID_F126_Autosar_BSW_Cluster_Versions_DID_F126_14_MODEMGMT_CLUSTER_SW_PATCH_VERSION
        enable-take-address=true, indirect-api=false, port=DataServices_DID_F126_Autosar_BSW_Cluster_Versions_DID_F126_1_DIAG_CLUSTER_VENDOR_ID
        enable-take-address=true, indirect-api=false, port=DataServices_DID_F126_Autosar_BSW_Cluster_Versions_DID_F126_41_LIN_CLUSTER_SW_MINOR_VERSION
        enable-take-address=true, indirect-api=false, port=DataServices_DID_F126_Autosar_BSW_Cluster_Versions_DID_F126_10_DIAG_CLUSTER_VCC_FIM_VERSION
        enable-take-address=true, indirect-api=false, port=DataServices_DID_F126_Autosar_BSW_Cluster_Versions_DID_F126_18_COM_CLUSTER_VENDOR_ID
        enable-take-address=true, indirect-api=false, port=DataServices_DID_F126_Autosar_BSW_Cluster_Versions_DID_F126_38_FLEXRAY_CLUSTER_AR_RELEASE_REVISION_VERSION
        enable-take-address=true, indirect-api=false, port=DataServices_DID_F126_Autosar_BSW_Cluster_Versions_DID_F126_32_FLEXRAY_CLUSTER_VENDOR_ID
        enable-take-address=true, indirect-api=false, port=DataServices_DID_F126_Autosar_BSW_Cluster_Versions_DID_F126_12_MODEMGMT_CLUSTER_SW_MAJOR_VERSION
        enable-take-address=true, indirect-api=false, port=DataServices_DID_F126_Autosar_BSW_Cluster_Versions_DID_F126_29_CAN_CLUSTER_AR_RELEASE_MAJOR_VERSION
        enable-take-address=true, indirect-api=false, port=DataServices_DID_F126_Autosar_BSW_Cluster_Versions_DID_F126_22_COM_CLUSTER_AR_RELEASE_MAJOR_VERSION
        enable-take-address=true, indirect-api=false, port=DataServices_DID_F126_Autosar_BSW_Cluster_Versions_DID_F126_44_LIN_CLUSTER_AR_RELEASE_MINOR_VERSION
        enable-take-address=true, indirect-api=false, port=DataServices_DID_F126_Autosar_BSW_Cluster_Versions_DID_F126_37_FLEXRAY_CLUSTER_AR_RELEASE_MINOR_VERSION
        enable-take-address=true, indirect-api=false, port=DataServices_DID_F126_Autosar_BSW_Cluster_Versions_DID_F126_45_LIN_CLUSTER_AR_RELEASE_REVISION_VERSION
        enable-take-address=true, indirect-api=false, port=DataServices_DID_F126_Autosar_BSW_Cluster_Versions_DID_F126_33_FLEXRAY_CLUSTER_SW_MAJOR_VERSION
        enable-take-address=true, indirect-api=false, port=DataServices_DID_E337_q_axis_current_setpoint_DID_E337_q_axis_current_setpoint
        enable-take-address=true, indirect-api=false, port=DataServices_DID_ED20_Complete_set_of_ECU_part_serial_numbers_Geely_BCD_part_003
        enable-take-address=true, indirect-api=false, port=DataServices_DID_ED20_Complete_set_of_ECU_part_serial_numbers_Geely_BCD_part_001
        enable-take-address=true, indirect-api=false, port=DataServices_DID_ED20_Complete_set_of_ECU_part_serial_numbers_Geely_BCD_part_002
        enable-take-address=true, indirect-api=false, port=DataServices_DID_ED20_Complete_set_of_ECU_part_serial_numbers_Geely_Reserved
        enable-take-address=true, indirect-api=false, port=DataServices_DID_ED20_Complete_set_of_ECU_part_serial_numbers_Geely_DID_F1AE_1_Total_number_of_ECU_Software_Part_Numbers
        enable-take-address=true, indirect-api=false, port=DataServices_DID_ED20_Complete_set_of_ECU_part_serial_numbers_Geely_DID_F18C_ECU_Serial_Number
        enable-take-address=true, indirect-api=false, port=DataServices_DID_ED20_Complete_set_of_ECU_part_serial_numbers_Geely_ASCII_part_{001..003}
        enable-take-address=true, indirect-api=false, port=DataServices_DID_ED20_Complete_set_of_ECU_part_serial_numbers_Geely_ASCII_part
        enable-take-address=true, indirect-api=false, port=DataServices_DID_ED20_Complete_set_of_ECU_part_serial_numbers_Geely_BCD_part
        enable-take-address=true, indirect-api=false, port=DataServices_DID_E339_d_axis_voltage_DID_E339_d_axis_voltage
        enable-take-address=true, indirect-api=false, port=DataServices_DID_EEB5_IEM_MGM_current_torque_DID_EEB5_IEMMGM_current_torque
        enable-take-address=true, indirect-api=false, port=DataServices_DID_F121_Primary_Bootloader_Diagnostic_Database_Part_Number_ASCII_part
        enable-take-address=true, indirect-api=false, port=DataServices_DID_F121_Primary_Bootloader_Diagnostic_Database_Part_Number_BCD_part
        enable-take-address=true, indirect-api=false, port=DataServices_DID_D0B5_SDB_version_SDB_version
        enable-take-address=true, indirect-api=false, port=DataServices_DID_D12F_Security_Constant_Level_11_12_DID_D12F_Security_Constant_Level_1112
        enable-take-address=true, indirect-api=false, port=DataServices_DID_E313_Active_discharge_status_DID_E313_Active_discharge_status
        enable-take-address=true, indirect-api=false, port=DataServices_DID_DD02_Vehicle_Battery_Voltage_DID_DD02_Vehicle_Battery_Voltage
        enable-take-address=true, indirect-api=false, port=DataServices_DID_E312_Wheel_Speed_DID_E312_Wheel_Speed
        enable-take-address=true, indirect-api=false, port=DataServices_DID_E363_Modulation_index_DID_E363_Modulation_index
        enable-take-address=true, indirect-api=false, port=DataServices_DID_D03A_swAuth_Public_Key_CheckSum_DID_D03A_swAuth_Public_Key_CheckSum
        enable-take-address=true, indirect-api=false, port=DataServices_DID_E347_IGBT_Max_Temperature_DID_E347_IGBT_Max_Temperature
        enable-take-address=true, indirect-api=false, port=DataServices_DID_F1AB_ECU_Delivery_Assembly_Part_Number_Geely_ASCII_part
        enable-take-address=true, indirect-api=false, port=DataServices_DID_F1AB_ECU_Delivery_Assembly_Part_Number_Geely_BCD_part
        enable-take-address=true, indirect-api=false, port=DataServices_DID_E336_d_axis_current_feedback_DID_E336_d_axis_current_feedback
        enable-take-address=true, indirect-api=false, port=DataServices_DID_EE9D_Transient_Phase_Current_B_DID_EE9D_Transient_Phase_Current_B
        enable-take-address=true, indirect-api=false, port=DataServices_DID_EE9F_Gate_Status_DID_EE9F_Gate_Status
        enable-take-address=true, indirect-api=false, port=DataServices_DID_E333_2002_State_2002_H_Ser
        enable-take-address=true, indirect-api=false, port=DataServices_DID_E333_2002_State_2002_Lu
        enable-take-address=true, indirect-api=false, port=DataServices_DID_E333_2002_State_2002_L_Ser
        enable-take-address=true, indirect-api=false, port=DataServices_DID_E333_2002_State_2002_Hu
        enable-take-address=true, indirect-api=false, port=DataServices_DID_E333_2002_State_2002_Lv
        enable-take-address=true, indirect-api=false, port=DataServices_DID_E333_2002_State_2002_Lw
        enable-take-address=true, indirect-api=false, port=DataServices_DID_E333_2002_State_2002_Hv
        enable-take-address=true, indirect-api=false, port=DataServices_DID_E333_2002_State_2002_Hw
        enable-take-address=true, indirect-api=false, port=DataServices_DID_E310_IEM_MGM_Derating_Status_DID_E310_IEMMGM_Derating_Status
        enable-take-address=true, indirect-api=false, port=DataServices_DID_EEBE_Offset_angle_status_DID_EEBE_Offset_angle_status
        enable-take-address=true, indirect-api=false, port=DataServices_Application_Diagnostic_Database_Part_Number_Partnumber_Variant
        enable-take-address=true, indirect-api=false, port=DataServices_Application_Diagnostic_Database_Part_Number_Partnumber_Main
        enable-take-address=true, indirect-api=false, port=DataServices_DID_0xEEC7_1_DID_EED2_SaftyTorque
        enable-take-address=true, indirect-api=false, port=DataServices_DID_E358_Resolve_angle_DID_E358_Resolve_angle
        enable-take-address=true, indirect-api=false, port=DataServices_DID_E357_Resolve_compensated_angle_DID_E357_Resolve_compensated_angle
        enable-take-address=true, indirect-api=false, port=DataServices_DID_E307_System_Mode_DID_E307_System_Mode
        enable-take-address=true, indirect-api=false, port=DataServices_DID_E305_Inverter_IGBT_Junction_Temp_DID_E305_Inverter_IGBT_Junction_Temp
        enable-take-address=true, indirect-api=false, port=DataServices_DID_F1AA_ECU_Core_Assembly_Part_Number_Geely_ASCII_part
        enable-take-address=true, indirect-api=false, port=DataServices_DID_F1AA_ECU_Core_Assembly_Part_Number_Geely_BCD_part
        enable-take-address=true, indirect-api=false, port=DataServices_DID_E301_HVDC_Current_DID_E301_HVDC_Current_
        enable-take-address=true, indirect-api=false, port=DataServices_DID_EF1C_EOL_config_word_B_DID_EF1C_EOL_config_word_B
        enable-take-address=true, indirect-api=false, port=DataServices_DID_EEBD_IEM_MGM_rotor_offset_angle_DID_EEBD_IEMMGM_rotor_offset_angle
        enable-take-address=true, indirect-api=false, port=DataServices_DID_E306_Motor_Temperature_DID_E306_Motor_Temperature
        enable-take-address=true, indirect-api=false, port=DataServices_DID_EED1_Safty_monitor_Fault_Indication_EED1_{1..3}
        enable-take-address=true, indirect-api=false, port=DataServices_DID_EED1_Safty_monitor_Fault_Indication_EED1_0
        enable-take-address=true, indirect-api=false, port=DataServices_DID_EEB7_ECM_Power_Limitation_minimum_DID_EEB7_ECM_Power_Limitation_minimum
        enable-take-address=true, indirect-api=false, port=DataServices_DID_F12E_ECU_Software_Part_Numbers_ASCII_part
        enable-take-address=true, indirect-api=false, port=DataServices_DID_F12E_ECU_Software_Part_Numbers_DID_F12E_1_ECU_Software
        enable-take-address=true, indirect-api=false, port=DataServices_DID_F12E_ECU_Software_Part_Numbers_BCD_part
        enable-take-address=true, indirect-api=false, port=DataServices_DID_F1AE_ECU_Software_Part_Numbers_Geely_DID_F1AE_1_Total_number_of_ECU_Software_Part_Numbers
        enable-take-address=true, indirect-api=false, port=DataServices_DID_F1AE_ECU_Software_Part_Numbers_Geely_ASCII_part
        enable-take-address=true, indirect-api=false, port=DataServices_DID_F1AE_ECU_Software_Part_Numbers_Geely_BCD_part
        enable-take-address=true, indirect-api=false, port=DataServices_DID_F125_Primary_Bootloader_Software_Part_Number_ASCII_part
        enable-take-address=true, indirect-api=false, port=DataServices_DID_F125_Primary_Bootloader_Software_Part_Number_BCD_part
        enable-take-address=true, indirect-api=false, port=DataServices_DID_EEFD_Sofware_Project_Version_DID_EEFD_Clutch_Control_Fault_Indication
        enable-take-address=true, indirect-api=false, port=DataServices_DID_E304_Actual_Torque_DID_E304_Actual_Torque
        enable-take-address=true, indirect-api=false, port=DataServices_DID_D134_Car_Mode_DID_D134_Car_Mode
        enable-take-address=true, indirect-api=false, port=DataServices_DID_E335_d_axis_current_setpoint_DID_E335_d_axis_current_setpoint
        enable-take-address=true, indirect-api=false, port=DataServices_DID_EEB2_Three_Phase_Motor_Current_RMS_Current_DID_EEB2_Three_Phase_Motor_Current_RMS_Current
        enable-take-address=true, indirect-api=false, port=DataServices_DID_E341_q_axis_voltage_DID_E341_q_axis_voltage
        enable-take-address=true, indirect-api=false, port=DataServices_DID_EE9A_Inverter_Coolant_Temperature_DID_EE9A_Inverter_Coolant_Temperature
        enable-take-address=true, indirect-api=false, port=DataServices_DID_EEB6_ECM_Power_Limitation_maximum_DID_EEB6_ECM_Power_Limitation_maximum
        enable-take-address=true, indirect-api=false, port=DataServices_DID_F1AF_ECU_Software_Extended_Part_Numbers_Geely_DID_F1AF_1_Total_number_of_ECU_Software_Part_Numbers
        enable-take-address=true, indirect-api=false, port=DataServices_DID_F1AF_ECU_Software_Extended_Part_Numbers_Geely_BCD_part_003
        enable-take-address=true, indirect-api=false, port=DataServices_DID_F1AF_ECU_Software_Extended_Part_Numbers_Geely_BCD_part_001
        enable-take-address=true, indirect-api=false, port=DataServices_DID_F1AF_ECU_Software_Extended_Part_Numbers_Geely_BCD_part_002
        enable-take-address=true, indirect-api=false, port=DataServices_DID_F1AF_ECU_Software_Extended_Part_Numbers_Geely_ASCII_part_{001..003}
        enable-take-address=true, indirect-api=false, port=DataServices_DID_F1AF_ECU_Software_Extended_Part_Numbers_Geely_ASCII_part
        enable-take-address=true, indirect-api=false, port=DataServices_DID_F1AF_ECU_Software_Extended_Part_Numbers_Geely_BCD_part
        enable-take-address=true, indirect-api=false, port=DataServices_DID_E331_Software_Version_DID_E331_2_BSW_Software_Version
        enable-take-address=true, indirect-api=false, port=DataServices_DID_E331_Software_Version_DID_E331_3_Calibration_Data_Software_Version
        enable-take-address=true, indirect-api=false, port=DataServices_DID_E331_Software_Version_DID_E331_1_ASW_Software_Version
        enable-take-address=true, indirect-api=false, port=DataServices_DID_EE9E_Transient_Phase_Current_C_DID_EE9E_Transient_Phase_Current_C
        enable-take-address=true, indirect-api=false, port=DataServices_DID_D005_High_Quiescent_Current_Fault_Identification_Data_DID_D005_5st_Usage_Mode_when_DID_is_triggered
        enable-take-address=true, indirect-api=false, port=DataServices_DID_D005_High_Quiescent_Current_Fault_Identification_Data_DID_D005_5st_System_Global_Time_the_time_when_th_C1151891
        enable-take-address=true, indirect-api=false, port=DataServices_DID_D005_High_Quiescent_Current_Fault_Identification_Data_DID_D005_1st_Usage_Mode_when_DID_is_triggered
        enable-take-address=true, indirect-api=false, port=DataServices_DID_D005_High_Quiescent_Current_Fault_Identification_Data_D005_4st_Functionality_Activity_Level_PNC39
        enable-take-address=true, indirect-api=false, port=DataServices_DID_D005_High_Quiescent_Current_Fault_Identification_Data_Bitfield_4th
        enable-take-address=true, indirect-api=false, port=DataServices_DID_D005_High_Quiescent_Current_Fault_Identification_Data_D005_1st_Functionality_Activity_Level_PNC26
        enable-take-address=true, indirect-api=false, port=DataServices_DID_D005_High_Quiescent_Current_Fault_Identification_Data_D005_1st_Functionality_Activity_Level_PNC27
        enable-take-address=true, indirect-api=false, port=DataServices_DID_D005_High_Quiescent_Current_Fault_Identification_Data_Bitfield_2th
        enable-take-address=true, indirect-api=false, port=DataServices_DID_D005_High_Quiescent_Current_Fault_Identification_Data_Functionality_Activity_Level_Detect_CPSR_Keep_Active_2st
        enable-take-address=true, indirect-api=false, port=DataServices_DID_D005_High_Quiescent_Current_Fault_Identification_Data_D005_1st_Functionality_Activity_Level_PNC29
        enable-take-address=true, indirect-api=false, port=DataServices_DID_D005_High_Quiescent_Current_Fault_Identification_Data_D005_1st_Functionality_Activity_Level_PNC24
        enable-take-address=true, indirect-api=false, port=DataServices_DID_D005_High_Quiescent_Current_Fault_Identification_Data_D005_1st_Functionality_Activity_Level_PNC25
        enable-take-address=true, indirect-api=false, port=DataServices_DID_D005_High_Quiescent_Current_Fault_Identification_Data_Reserved_PNC_2st
        enable-take-address=true, indirect-api=false, port=DataServices_DID_D005_High_Quiescent_Current_Fault_Identification_Data_D005_1st_Functionality_Activity_Level_PNC30
        enable-take-address=true, indirect-api=false, port=DataServices_DID_D005_High_Quiescent_Current_Fault_Identification_Data_Functionality_Activity_Level_Detect_CPSR_Keep_Active_4st
        enable-take-address=true, indirect-api=false, port=DataServices_DID_D005_High_Quiescent_Current_Fault_Identification_Data_Reserved_PNC_4st
        enable-take-address=true, indirect-api=false, port=DataServices_DID_D005_High_Quiescent_Current_Fault_Identification_Data_Functionality_Activity_Level_Detect_Motor_Speed_AE735753
        enable-take-address=true, indirect-api=false, port=DataServices_DID_D005_High_Quiescent_Current_Fault_Identification_Data_D005_2st_Functionality_Activity_Level_PNC39
        enable-take-address=true, indirect-api=false, port=DataServices_DID_D005_High_Quiescent_Current_Fault_Identification_Data_Functionality_Activity_Level_Detect_Motor_Speed_AE736657
        enable-take-address=true, indirect-api=false, port=DataServices_DID_D005_High_Quiescent_Current_Fault_Identification_Data_Functionality_Activity_Level_Detect_Motor_Speed_AE735ED5
        enable-take-address=true, indirect-api=false, port=DataServices_DID_D005_High_Quiescent_Current_Fault_Identification_Data_D005_2st_Functionality_Activity_Level_PNC35
        enable-take-address=true, indirect-api=false, port=DataServices_DID_D005_High_Quiescent_Current_Fault_Identification_Data_D005_4st_Functionality_Activity_Level_PNC29
        enable-take-address=true, indirect-api=false, port=DataServices_DID_D005_High_Quiescent_Current_Fault_Identification_Data_DID_D005_5st_Global_time_when_Functionality_Acti_183F5278
        enable-take-address=true, indirect-api=false, port=DataServices_DID_D005_High_Quiescent_Current_Fault_Identification_Data_DID_D005_2st_Usage_Mode_when_DID_is_triggered
        enable-take-address=true, indirect-api=false, port=DataServices_DID_D005_High_Quiescent_Current_Fault_Identification_Data_D005_2st_Functionality_Activity_Level_PNC30
        enable-take-address=true, indirect-api=false, port=DataServices_DID_D005_High_Quiescent_Current_Fault_Identification_Data_D005_4st_Functionality_Activity_Level_PNC25
        enable-take-address=true, indirect-api=false, port=DataServices_DID_D005_High_Quiescent_Current_Fault_Identification_Data_Reserved_Data_Field_4st
        enable-take-address=true, indirect-api=false, port=DataServices_DID_D005_High_Quiescent_Current_Fault_Identification_Data_D005_4st_Functionality_Activity_Level_PNC26
        enable-take-address=true, indirect-api=false, port=DataServices_DID_D005_High_Quiescent_Current_Fault_Identification_Data_D005_4st_Functionality_Activity_Level_PNC27
        enable-take-address=true, indirect-api=false, port=DataServices_DID_D005_High_Quiescent_Current_Fault_Identification_Data_Functionality_Activity_Level_Detect_DC_Bus_volta_2AFD19A5
        enable-take-address=true, indirect-api=false, port=DataServices_DID_D005_High_Quiescent_Current_Fault_Identification_Data_DID_D005_3st_System_Global_Time_the_time_when_th_75ED068F
        enable-take-address=true, indirect-api=false, port=DataServices_DID_D005_High_Quiescent_Current_Fault_Identification_Data_D005_3st_Functionality_Activity_Level_PNC30
        enable-take-address=true, indirect-api=false, port=DataServices_DID_D005_High_Quiescent_Current_Fault_Identification_Data_Reserved_Data_Field_2st
        enable-take-address=true, indirect-api=false, port=DataServices_DID_D005_High_Quiescent_Current_Fault_Identification_Data_DID_D005_2st_Global_time_when_Functionality_Acti_75CD35A0
        enable-take-address=true, indirect-api=false, port=DataServices_DID_D005_High_Quiescent_Current_Fault_Identification_Data_D005_3st_Functionality_Activity_Level_PNC25
        enable-take-address=true, indirect-api=false, port=DataServices_DID_D005_High_Quiescent_Current_Fault_Identification_Data_D005_3st_Functionality_Activity_Level_PNC24
        enable-take-address=true, indirect-api=false, port=DataServices_DID_D005_High_Quiescent_Current_Fault_Identification_Data_D005_3st_Functionality_Activity_Level_PNC27
        enable-take-address=true, indirect-api=false, port=DataServices_DID_D005_High_Quiescent_Current_Fault_Identification_Data_D005_3st_Functionality_Activity_Level_PNC26
        enable-take-address=true, indirect-api=false, port=DataServices_DID_D005_High_Quiescent_Current_Fault_Identification_Data_D005_5st_Functionality_Activity_Level_PNC39
        enable-take-address=true, indirect-api=false, port=DataServices_DID_D005_High_Quiescent_Current_Fault_Identification_Data_D005_3st_Functionality_Activity_Level_PNC29
        enable-take-address=true, indirect-api=false, port=DataServices_DID_D005_High_Quiescent_Current_Fault_Identification_Data_DID_D005_1_1st_System_Global_Time_the_time_when_2A73953F
        enable-take-address=true, indirect-api=false, port=DataServices_DID_D005_High_Quiescent_Current_Fault_Identification_Data_D005_2st_Functionality_Activity_Level_PNC29
        enable-take-address=true, indirect-api=false, port=DataServices_DID_D005_High_Quiescent_Current_Fault_Identification_Data_Functionality_Activity_Level_Detect_DC_Bus_volta_2AFD28A9
        enable-take-address=true, indirect-api=false, port=DataServices_DID_D005_High_Quiescent_Current_Fault_Identification_Data_D005_4st_Functionality_Activity_Level_PNC35
        enable-take-address=true, indirect-api=false, port=DataServices_DID_D005_High_Quiescent_Current_Fault_Identification_Data_D005_2st_Functionality_Activity_Level_PNC27
        enable-take-address=true, indirect-api=false, port=DataServices_DID_D005_High_Quiescent_Current_Fault_Identification_Data_DID_D005_4st_System_Global_Time_the_time_when_th_9B810F90
        enable-take-address=true, indirect-api=false, port=DataServices_DID_D005_High_Quiescent_Current_Fault_Identification_Data_D005_2st_Functionality_Activity_Level_PNC26
        enable-take-address=true, indirect-api=false, port=DataServices_DID_D005_High_Quiescent_Current_Fault_Identification_Data_D005_2st_Functionality_Activity_Level_PNC25
        enable-take-address=true, indirect-api=false, port=DataServices_DID_D005_High_Quiescent_Current_Fault_Identification_Data_D005_4st_Functionality_Activity_Level_PNC30
        enable-take-address=true, indirect-api=false, port=DataServices_DID_D005_High_Quiescent_Current_Fault_Identification_Data_D005_2st_Functionality_Activity_Level_PNC24
        enable-take-address=true, indirect-api=false, port=DataServices_DID_D005_High_Quiescent_Current_Fault_Identification_Data_DID_D005_3st_Global_time_when_Functionality_Acti_A45DA93A
        enable-take-address=true, indirect-api=false, port=DataServices_DID_D005_High_Quiescent_Current_Fault_Identification_Data_D005_5st_Functionality_Activity_Level_PNC35
        enable-take-address=true, indirect-api=false, port=DataServices_DID_D005_High_Quiescent_Current_Fault_Identification_Data_Bitfield_3th
        enable-take-address=true, indirect-api=false, port=DataServices_DID_D005_High_Quiescent_Current_Fault_Identification_Data_DID_D005_2st_System_Global_Time_the_time_when_th_5058FD8E
        enable-take-address=true, indirect-api=false, port=DataServices_DID_D005_High_Quiescent_Current_Fault_Identification_Data_Functionality_Activity_Level_Detect_CPSR_Keep_Active_1st
        enable-take-address=true, indirect-api=false, port=DataServices_DID_D005_High_Quiescent_Current_Fault_Identification_Data_Bitfield_1th
        enable-take-address=true, indirect-api=false, port=DataServices_DID_D005_High_Quiescent_Current_Fault_Identification_Data_DID_D005_3st_Usage_Mode_when_DID_is_triggered
        enable-take-address=true, indirect-api=false, port=DataServices_DID_D005_High_Quiescent_Current_Fault_Identification_Data_D005_5st_Functionality_Activity_Level_PNC30
        enable-take-address=true, indirect-api=false, port=DataServices_DID_D005_High_Quiescent_Current_Fault_Identification_Data_D005_3st_Functionality_Activity_Level_PNC35
        enable-take-address=true, indirect-api=false, port=DataServices_DID_D005_High_Quiescent_Current_Fault_Identification_Data_Reserved_PNC_1st
        enable-take-address=true, indirect-api=false, port=DataServices_DID_D005_High_Quiescent_Current_Fault_Identification_Data_DID_D005_4st_Global_time_when_Functionality_Acti_F1BD651E
        enable-take-address=true, indirect-api=false, port=DataServices_DID_D005_High_Quiescent_Current_Fault_Identification_Data_Functionality_Activity_Level_Detect_CPSR_Keep_Active_3st
        enable-take-address=true, indirect-api=false, port=DataServices_DID_D005_High_Quiescent_Current_Fault_Identification_Data_Reserved_PNC_5st
        enable-take-address=true, indirect-api=false, port=DataServices_DID_D005_High_Quiescent_Current_Fault_Identification_Data_D005_5st_Functionality_Activity_Level_PNC29
        enable-take-address=true, indirect-api=false, port=DataServices_DID_D005_High_Quiescent_Current_Fault_Identification_Data_Functionality_Activity_Level_Detect_DC_Bus_volta_BF51DF82
        enable-take-address=true, indirect-api=false, port=DataServices_DID_D005_High_Quiescent_Current_Fault_Identification_Data_D005_3st_Functionality_Activity_Level_PNC39
        enable-take-address=true, indirect-api=false, port=DataServices_DID_D005_High_Quiescent_Current_Fault_Identification_Data_Functionality_Activity_Level_Detect_CPSR_Keep_Active_5st
        enable-take-address=true, indirect-api=false, port=DataServices_DID_D005_High_Quiescent_Current_Fault_Identification_Data_D005_5st_Functionality_Activity_Level_PNC26
        enable-take-address=true, indirect-api=false, port=DataServices_DID_D005_High_Quiescent_Current_Fault_Identification_Data_D005_5st_Functionality_Activity_Level_PNC27
        enable-take-address=true, indirect-api=false, port=DataServices_DID_D005_High_Quiescent_Current_Fault_Identification_Data_Reserved_PNC_3st
        enable-take-address=true, indirect-api=false, port=DataServices_DID_D005_High_Quiescent_Current_Fault_Identification_Data_D005_4st_Functionality_Activity_Level_PNC24
        enable-take-address=true, indirect-api=false, port=DataServices_DID_D005_High_Quiescent_Current_Fault_Identification_Data_Functionality_Activity_Level_Detect_Motor_Speed_AE736296
        enable-take-address=true, indirect-api=false, port=DataServices_DID_D005_High_Quiescent_Current_Fault_Identification_Data_Functionality_Activity_Level_Detect_Motor_Speed_AE735B14
        enable-take-address=true, indirect-api=false, port=DataServices_DID_D005_High_Quiescent_Current_Fault_Identification_Data_DID_D005_2_1st_Global_time_when_Functionality_Ac_89793B23
        enable-take-address=true, indirect-api=false, port=DataServices_DID_D005_High_Quiescent_Current_Fault_Identification_Data_Reserved_Data_Field_3st
        enable-take-address=true, indirect-api=false, port=DataServices_DID_D005_High_Quiescent_Current_Fault_Identification_Data_Functionality_Activity_Level_Detect_DC_Bus_volta_2AFD1D66
        enable-take-address=true, indirect-api=false, port=DataServices_DID_D005_High_Quiescent_Current_Fault_Identification_Data_Reserved_Data_Field_5st
        enable-take-address=true, indirect-api=false, port=DataServices_DID_D005_High_Quiescent_Current_Fault_Identification_Data_D005_5st_Functionality_Activity_Level_PNC24
        enable-take-address=true, indirect-api=false, port=DataServices_DID_D005_High_Quiescent_Current_Fault_Identification_Data_D005_5st_Functionality_Activity_Level_PNC25
        enable-take-address=true, indirect-api=false, port=DataServices_DID_D005_High_Quiescent_Current_Fault_Identification_Data_Reserved_Data_Field_1st
        enable-take-address=true, indirect-api=false, port=DataServices_DID_D005_High_Quiescent_Current_Fault_Identification_Data_D005_1st_Functionality_Activity_Level_PNC39
        enable-take-address=true, indirect-api=false, port=DataServices_DID_D005_High_Quiescent_Current_Fault_Identification_Data_D005_1st_Functionality_Activity_Level_PNC35
        enable-take-address=true, indirect-api=false, port=DataServices_DID_D005_High_Quiescent_Current_Fault_Identification_Data_DID_D005_4st_Usage_Mode_when_DID_is_triggered
        enable-take-address=true, indirect-api=false, port=DataServices_DID_D005_High_Quiescent_Current_Fault_Identification_Data_Bitfield_5th
        enable-take-address=true, indirect-api=false, port=DataServices_DID_D005_High_Quiescent_Current_Fault_Identification_Data_Functionality_Activity_Level_Detect_DC_Bus_volta_2AFD24E8
        enable-take-address=true, indirect-api=false, port=DataServices_DID_40E0_Secret_Key_Immobilizer_Target_3_DID_40DF_Secret_Key_Immobilizer_Target_2
        enable-take-address=true, indirect-api=false, port=DataServices_DID_EEB8_HV_voltage_received_from_BECM_DID_EEB8_HV_voltage_received_from_BECM
        enable-take-address=true, indirect-api=false, port=DataServices_DID_E348_Phase_U_PWM_duty_DID_E348_Phase_U_PWM_duty
        enable-take-address=true, indirect-api=false, port=DataServices_DID_D211_Network_Management_History_Propulsion_CAN_DID_D211_20_10th_Latest_State_Global_Real_Time
        enable-take-address=true, indirect-api=false, port=DataServices_DID_D211_Network_Management_History_Propulsion_CAN_DID_D211_1_Latest_State_NM_History
        enable-take-address=true, indirect-api=false, port=DataServices_DID_D211_Network_Management_History_Propulsion_CAN_DID_D211_16_8th_Latest_State_Global_Real_Time
        enable-take-address=true, indirect-api=false, port=DataServices_DID_D211_Network_Management_History_Propulsion_CAN_DID_D211_11_6th_Latest_State_NM_History
        enable-take-address=true, indirect-api=false, port=DataServices_DID_D211_Network_Management_History_Propulsion_CAN_DID_D211_4_2nd_Latest_State_Global_Real_Time
        enable-take-address=true, indirect-api=false, port=DataServices_DID_D211_Network_Management_History_Propulsion_CAN_DID_D211_2_Latest_State_Global_Real_Time
        enable-take-address=true, indirect-api=false, port=DataServices_DID_D211_Network_Management_History_Propulsion_CAN_DID_D211_12_6th_Latest_State_Global_Real_Time
        enable-take-address=true, indirect-api=false, port=DataServices_DID_D211_Network_Management_History_Propulsion_CAN_DID_D211_5_3rd_Latest_State_NM_History
        enable-take-address=true, indirect-api=false, port=DataServices_DID_D211_Network_Management_History_Propulsion_CAN_DID_D211_17_9th_Latest_State_NM_History
        enable-take-address=true, indirect-api=false, port=DataServices_DID_D211_Network_Management_History_Propulsion_CAN_DID_D211_9_5th_Latest_State_NM_History
        enable-take-address=true, indirect-api=false, port=DataServices_DID_D211_Network_Management_History_Propulsion_CAN_DID_D211_13_7th_Latest_State_NM_History
        enable-take-address=true, indirect-api=false, port=DataServices_DID_D211_Network_Management_History_Propulsion_CAN_DID_D211_8_4th_Latest_State_Global_Real_Time
        enable-take-address=true, indirect-api=false, port=DataServices_DID_D211_Network_Management_History_Propulsion_CAN_DID_D211_10_5th_Latest_State_Global_Real_Time
        enable-take-address=true, indirect-api=false, port=DataServices_DID_D211_Network_Management_History_Propulsion_CAN_DID_D211_18_9th_Latest_State_Global_Real_Time
        enable-take-address=true, indirect-api=false, port=DataServices_DID_D211_Network_Management_History_Propulsion_CAN_DID_D211_6_3rd_Latest_State_Global_Real_Time
        enable-take-address=true, indirect-api=false, port=DataServices_DID_D211_Network_Management_History_Propulsion_CAN_DID_D211_15_8th_Latest_State_NM_History
        enable-take-address=true, indirect-api=false, port=DataServices_DID_D211_Network_Management_History_Propulsion_CAN_DID_D211_19_10th_Latest_State_NM_History
        enable-take-address=true, indirect-api=false, port=DataServices_DID_D211_Network_Management_History_Propulsion_CAN_DID_D211_14_7th_Latest_State_Global_Real_Time
        enable-take-address=true, indirect-api=false, port=DataServices_DID_D211_Network_Management_History_Propulsion_CAN_DID_D211_3_2nd_Latest_State_NM_History
        enable-take-address=true, indirect-api=false, port=DataServices_DID_D211_Network_Management_History_Propulsion_CAN_DID_D211_7_4th_Latest_State_NM_History
        enable-take-address=true, indirect-api=false, port=DataServices_DID_E303_Motor_Speed_DID_E303_Motor_Speed_
        enable-take-address=true, indirect-api=false, port=DataServices_DID_E324_Motor_Derating_reason_of_IEM_MGM_DID_E324_Motor_Derating_reason_of_IEMMGM
        enable-take-address=true, indirect-api=false, port=DataServices_DID_DD01_Total_Distance_DID_DD01_Total_Distance
        enable-take-address=true, indirect-api=false, port=DataServices_DID_E320_System_Mode_Mismatch_DID_E320_System_Mode_Mismatch
        enable-take-address=true, indirect-api=false, port=DataServices_DID_F12F_ECU_Software_Extended_Part_Numbers_ASCII_part_009
        enable-take-address=true, indirect-api=false, port=DataServices_DID_F12F_ECU_Software_Extended_Part_Numbers_BCD_part_005
        enable-take-address=true, indirect-api=false, port=DataServices_DID_F12F_ECU_Software_Extended_Part_Numbers_BCD_part_006
        enable-take-address=true, indirect-api=false, port=DataServices_DID_F12F_ECU_Software_Extended_Part_Numbers_BCD_part_003
        enable-take-address=true, indirect-api=false, port=DataServices_DID_F12F_ECU_Software_Extended_Part_Numbers_BCD_part_004
        enable-take-address=true, indirect-api=false, port=DataServices_DID_F12F_ECU_Software_Extended_Part_Numbers_ASCII_part_005
        enable-take-address=true, indirect-api=false, port=DataServices_DID_F12F_ECU_Software_Extended_Part_Numbers_BCD_part_001
        enable-take-address=true, indirect-api=false, port=DataServices_DID_F12F_ECU_Software_Extended_Part_Numbers_ASCII_part_006
        enable-take-address=true, indirect-api=false, port=DataServices_DID_F12F_ECU_Software_Extended_Part_Numbers_BCD_part_002
        enable-take-address=true, indirect-api=false, port=DataServices_DID_F12F_ECU_Software_Extended_Part_Numbers_ASCII_part_007
        enable-take-address=true, indirect-api=false, port=DataServices_DID_F12F_ECU_Software_Extended_Part_Numbers_ASCII_part_008
        enable-take-address=true, indirect-api=false, port=DataServices_DID_F12F_ECU_Software_Extended_Part_Numbers_BCD_part
        enable-take-address=true, indirect-api=false, port=DataServices_DID_F12F_ECU_Software_Extended_Part_Numbers_DID_F12F_1_Total_number_of_ECU_Software_Part_Numbers
        enable-take-address=true, indirect-api=false, port=DataServices_DID_F12F_ECU_Software_Extended_Part_Numbers_ASCII_part_{001..004}
        enable-take-address=true, indirect-api=false, port=DataServices_DID_F12F_ECU_Software_Extended_Part_Numbers_ASCII_part
        enable-take-address=true, indirect-api=false, port=DataServices_DID_F12F_ECU_Software_Extended_Part_Numbers_BCD_part_009
        enable-take-address=true, indirect-api=false, port=DataServices_DID_F12F_ECU_Software_Extended_Part_Numbers_BCD_part_007
        enable-take-address=true, indirect-api=false, port=DataServices_DID_F12F_ECU_Software_Extended_Part_Numbers_BCD_part_008
        enable-take-address=true, indirect-api=false, port=DataServices_DID_EEC4_Charging_Power_Sustain_Relay_CPSR_Voltage_DID_EEC4_Charging_Power_Sustain_RelayCPSR_Voltage
        enable-take-address=true, indirect-api=false, port=DataServices_DID_F12B_ECU_Delivery_Assembly_Part_Number_ASCII_part
        enable-take-address=true, indirect-api=false, port=DataServices_DID_F12B_ECU_Delivery_Assembly_Part_Number_BCD_part
        enable-take-address=true, indirect-api=false, port=DataServices_DID_F12A_ECU_Core_Assembly_Part_Number_ASCII_part
        enable-take-address=true, indirect-api=false, port=DataServices_DID_F12A_ECU_Core_Assembly_Part_Number_BCD_part
        enable-take-address=true, indirect-api=false, port=DataServices_DID_E346_ECM_Torque_Allowed_Status_DID_E346_ECM_Torque_Allowed_Status
        enable-take-address=true, indirect-api=false, port=DataServices_DID_EED3_Safety_speed_DID_EED3_Safety_speed
        enable-take-address=true, indirect-api=false, port=DataServices_DID_DD0C_Electric_Power_Level_DID_DD0C_Electric_Power_Level
        enable-take-address=true, indirect-api=false, port=DataServices_DID_F1A0_Application_Diagnostic_Database_Part_Number_Geely_ASCII_part
        enable-take-address=true, indirect-api=false, port=DataServices_DID_F1A0_Application_Diagnostic_Database_Part_Number_Geely_BCD_part
        enable-take-address=true, indirect-api=false, port=DataServices_DID_E309_ECM_Mode_Request_DID_E309_ECM_Mode_Request
        enable-take-address=true, indirect-api=false, port=DataServices_DID_E103_Car_Configuration_Parameter_Faults_DID_E103_3_1st_parameter_invalid_value
        enable-take-address=true, indirect-api=false, port=DataServices_DID_E103_Car_Configuration_Parameter_Faults_DID_E103_1_Number_of_invalid_car_configuration_parameter_value_7E36D2F5
        enable-take-address=true, indirect-api=false, port=DataServices_DID_E103_Car_Configuration_Parameter_Faults_DID_E103_21_10th_parameter_invalid_value
        enable-take-address=true, indirect-api=false, port=DataServices_DID_E103_Car_Configuration_Parameter_Faults_DID_E103_20_10th_parameter_number_of_the_car_configuration_dat_86F3B3DF
        enable-take-address=true, indirect-api=false, port=DataServices_DID_E103_Car_Configuration_Parameter_Faults_DID_E103_16_8th_parameter_number_of_the_car_configuration_data_2E2F0597
        enable-take-address=true, indirect-api=false, port=DataServices_DID_E103_Car_Configuration_Parameter_Faults_DID_E103_12_6th_parameter_number_of_the_car_configuration_data_E81803DD
        enable-take-address=true, indirect-api=false, port=DataServices_DID_E103_Car_Configuration_Parameter_Faults_DID_E103_11_5th_parameter_invalid_value
        enable-take-address=true, indirect-api=false, port=DataServices_DID_E103_Car_Configuration_Parameter_Faults_DID_E103_15_7th_parameter_invalid_value
        enable-take-address=true, indirect-api=false, port=DataServices_DID_E103_Car_Configuration_Parameter_Faults_DID_E103_6_3rd_parameter_number_of_the_car_configuration_data_DA502437
        enable-take-address=true, indirect-api=false, port=DataServices_DID_E103_Car_Configuration_Parameter_Faults_DID_E103_10_5th_parameter_number_of_the_car_configuration_data_450C8300
        enable-take-address=true, indirect-api=false, port=DataServices_DID_E103_Car_Configuration_Parameter_Faults_DID_E103_8_4th_parameter_number_of_the_car_configuration_data_125EA492
        enable-take-address=true, indirect-api=false, port=DataServices_DID_E103_Car_Configuration_Parameter_Faults_DID_E103_5_2nd_parameter_invalid_value
        enable-take-address=true, indirect-api=false, port=DataServices_DID_E103_Car_Configuration_Parameter_Faults_DID_E103_18_9th_parameter_number_of_the_car_configuration_data_D13A8674
        enable-take-address=true, indirect-api=false, port=DataServices_DID_E103_Car_Configuration_Parameter_Faults_DID_E103_4_2nd_parameter_number_of_the_car_configuration_data_0046C356
        enable-take-address=true, indirect-api=false, port=DataServices_DID_E103_Car_Configuration_Parameter_Faults_DID_E103_14_7th_parameter_number_of_the_car_configuration_data_8B2384BA
        enable-take-address=true, indirect-api=false, port=DataServices_DID_E103_Car_Configuration_Parameter_Faults_DID_E103_19_9th_parameter_invalid_value
        enable-take-address=true, indirect-api=false, port=DataServices_DID_E103_Car_Configuration_Parameter_Faults_DID_E103_9_4th_parameter_invalid_value
        enable-take-address=true, indirect-api=false, port=DataServices_DID_E103_Car_Configuration_Parameter_Faults_DID_E103_17_8th_parameter_invalid_value
        enable-take-address=true, indirect-api=false, port=DataServices_DID_E103_Car_Configuration_Parameter_Faults_DID_E103_13_6th_parameter_invalid_value
        enable-take-address=true, indirect-api=false, port=DataServices_DID_E103_Car_Configuration_Parameter_Faults_DID_E103_2_1st_parameter_number_of_the_car_configuration_data_C808D86E
        enable-take-address=true, indirect-api=false, port=DataServices_DID_E103_Car_Configuration_Parameter_Faults_DID_E103_7_3rd_parameter_invalid_value
        enable-take-address=true, indirect-api=false, port=DataServices_DID_E311_Crash_Status_DID_E311_Crash_Status
        enable-take-address=true, indirect-api=false, port=DataServices_DID_EEC5_ImobEng2_node_status_DID_EEC5_ImobEng2_node_status
        enable-take-address=true, indirect-api=false, port=DataServices_DID_EF0A_Active_Discharge_Time_DID_EF0A_Active_Discharge_Time
        enable-take-address=true, indirect-api=false, port=Dcm
